VERSION ""

NS_ :

BS_:

BU_: BCM TPMS PEPS IC MP5 DDWS NV EATC TAC ESCL GW

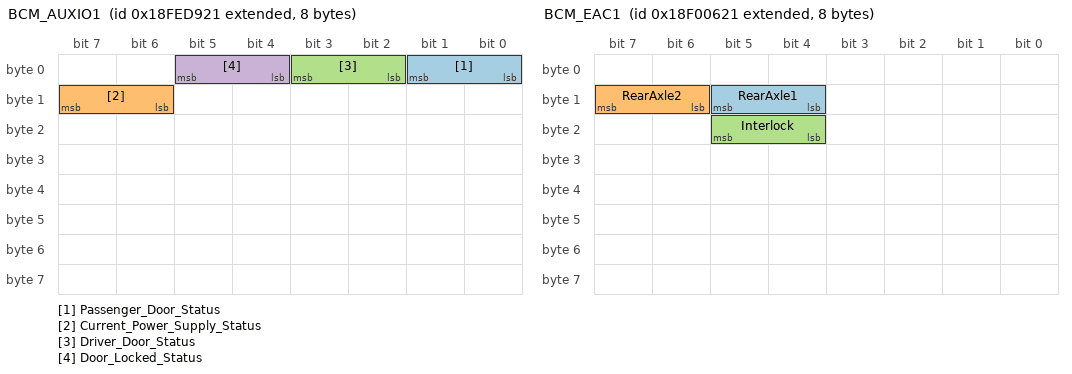
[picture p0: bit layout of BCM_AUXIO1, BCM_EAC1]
BO_ 2566838561 BCM_AUXIO1: 8 BCM
 SG_ Passenger_Door_Status : 0|2@1+ (1,0) [0|3] ""  PEPS,IC,MP5,GW
 SG_ Current_Power_Supply_Status : 14|2@1+ (1,0) [0|3] ""  MP5,EATC,GW
 SG_ Driver_Door_Status : 2|2@1+ (1,0) [0|3] ""  PEPS,IC,MP5,DDWS,GW
 SG_ Door_Locked_Status : 4|2@1+ (1,0) [0|3] ""  PEPS,GW

BO_ 2565867041 BCM_EAC1: 8 BCM
 SG_ RearAxle1 : 12|2@1+ (1,0) [0|3] ""  IC,MP5,GW
 SG_ RearAxle2 : 14|2@1+ (1,0) [0|3] ""  IC,MP5,GW
 SG_ Interlock : 20|2@1+ (1,0) [0|3] ""  IC,MP5,GW

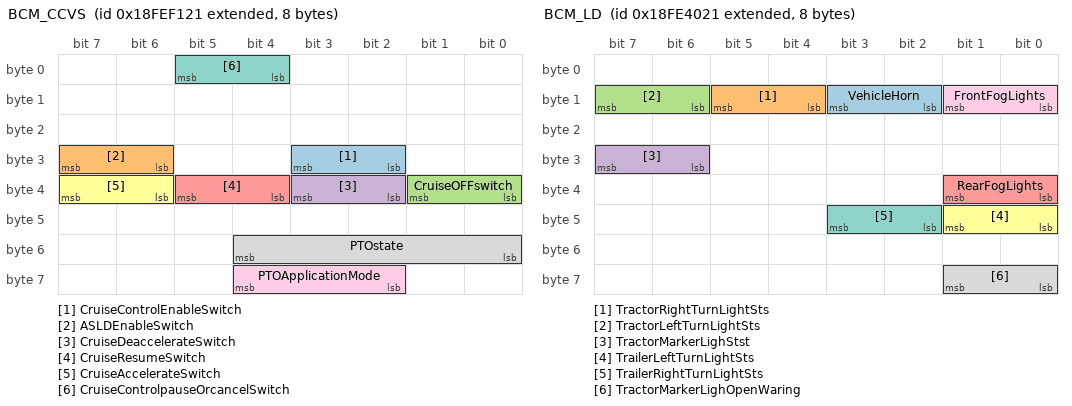
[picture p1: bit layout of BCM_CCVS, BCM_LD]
BO_ 2566844705 BCM_CCVS: 8 BCM
 SG_ CruiseControlEnableSwitch : 26|2@1+ (1,0) [0|3] ""  IC,GW
 SG_ ASLDEnableSwitch : 30|2@1+ (1,0) [0|3] ""  IC,GW
 SG_ CruiseOFFswitch : 32|2@1+ (1,0) [0|3] ""  IC,GW
 SG_ CruiseDeaccelerateSwitch : 34|2@1+ (1,0) [0|3] ""  IC,GW
 SG_ CruiseResumeSwitch : 36|2@1+ (1,0) [0|3] ""  IC,GW
 SG_ CruiseAccelerateSwitch : 38|2@1+ (1,0) [0|3] ""  IC,GW
 SG_ CruiseControlpauseOrcancelSwitch : 4|2@1+ (1,0) [0|3] ""  IC,GW
 SG_ PTOstate : 48|5@1+ (1,0) [0|31] ""  IC,GW
 SG_ PTOApplicationMode : 58|3@1+ (1,0) [0|7] ""  GW

BO_ 2566799393 BCM_LD: 8 BCM
 SG_ VehicleHorn : 10|2@1+ (1,0) [0|3] ""  TAC,GW
 SG_ TractorRightTurnLightSts : 12|2@1+ (1,0) [0|3] ""  IC,MP5,GW
 SG_ TractorLeftTurnLightSts : 14|2@1+ (1,0) [0|3] ""  IC,MP5,GW
 SG_ TractorMarkerLighStst : 30|2@1+ (1,0) [0|3] ""  IC,MP5,DDWS,NV,EATC,GW
 SG_ RearFogLights : 32|2@1+ (1,0) [0|3] ""  IC,MP5,GW
 SG_ TrailerLeftTurnLightSts : 40|2@1+ (1,0) [0|3] ""  IC,DDWS,GW
 SG_ TrailerRightTurnLightSts : 42|2@1+ (1,0) [0|3] ""  IC,DDWS,GW
 SG_ TractorMarkerLighOpenWaring : 56|2@1+ (1,0) [0|3] ""  IC,GW
 SG_ FrontFogLights : 8|2@1+ (1,0) [0|3] ""  IC,MP5,GW

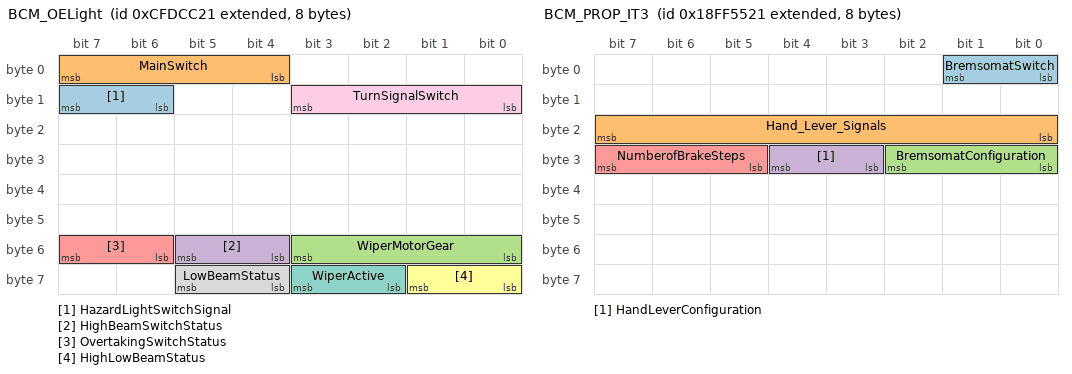
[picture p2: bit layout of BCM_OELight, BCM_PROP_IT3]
BO_ 2365443105 BCM_OELight: 8 BCM
 SG_ HazardLightSwitchSignal : 14|2@1+ (1,0) [0|3] ""  MP5,GW
 SG_ MainSwitch : 4|4@1+ (1,0) [0|15] ""  MP5,GW
 SG_ WiperMotorGear : 48|4@1+ (1,0) [0|15] ""  GW
 SG_ HighBeamSwitchStatus : 52|2@1+ (1,0) [0|3] ""  GW
 SG_ OvertakingSwitchStatus : 54|2@1+ (1,0) [0|3] ""  GW
 SG_ HighLowBeamStatus : 56|2@1+ (1,0) [0|3] ""  MP5,NV,GW
 SG_ WiperActive : 58|2@1+ (1,0) [0|3] ""  IC,GW
 SG_ LowBeamStatus : 60|2@1+ (1,0) [0|3] ""  MP5,NV,GW
 SG_ TurnSignalSwitch : 8|4@1+ (1,0) [0|15] ""  DDWS,GW

BO_ 2348875809 BCM_TC1: 8 BCM
 SG_ ReverseGear : 16|8@1+ (1,0) [0|255] ""  MP5,DDWS,GW
 SG_ RearviewMirrorHeating : 42|2@1+ (1,0) [0|3] ""  EATC,GW

BO_ 2566870305 BCM_PROP_IT3: 8 BCM
 SG_ BremsomatSwitch : 0|2@1+ (1,0) [0|3] ""  IC,GW
 SG_ Hand_Lever_Signals : 16|8@1+ (1,0) [0|63] ""  IC,GW
 SG_ BremsomatConfiguration : 24|3@1+ (1,0) [0|7] ""  IC,GW
 SG_ HandLeverConfiguration : 27|2@1+ (1,0) [0|3] ""  IC,GW
 SG_ NumberofBrakeSteps : 29|3@1+ (1,0) [0|7] ""  IC,GW

BO_ 2563768353 BCM_LightP: 8 BCM
 SG_ SwitBackLlluminatBrightPercent : 8|8@1+ (0.4,0) [0|100] "%"  PEPS,IC,EATC,GW

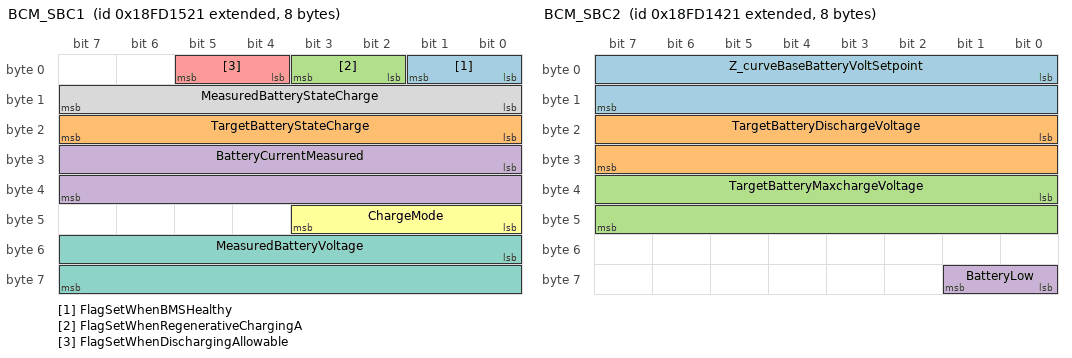
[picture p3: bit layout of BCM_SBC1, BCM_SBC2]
BO_ 2566722849 BCM_SBC1: 8 BCM
 SG_ FlagSetWhenBMSHealthy : 0|2@1+ (1,0) [0|3] ""  GW
 SG_ TargetBatteryStateCharge : 16|8@1+ (0.5,-10) [-10|110] ""  GW
 SG_ FlagSetWhenRegenerativeChargingA : 2|2@1+ (1,0) [0|3] ""  GW
 SG_ BatteryCurrentMeasured : 24|16@1+ (0.0305,-1600) [-1600|398.8] ""  GW
 SG_ FlagSetWhenDischargingAllowable : 4|2@1+ (1,0) [0|3] ""  GW
 SG_ ChargeMode : 40|4@1+ (1,0) [0|15] ""  GW
 SG_ MeasuredBatteryVoltage : 48|16@1+ (0.557,-1500) [-1500|35000] ""  GW
 SG_ MeasuredBatteryStateCharge : 8|8@1+ (0.5,-10) [-10|110] ""  GW

BO_ 2566722593 BCM_SBC2: 8 BCM
 SG_ Z_curveBaseBatteryVoltSetpoint : 0|16@1+ (0.557,-1500) [-1500|35000] "mV"  GW
 SG_ TargetBatteryDischargeVoltage : 16|16@1+ (0.557,-1500) [-1500|35000] "mV"  GW
 SG_ TargetBatteryMaxchargeVoltage : 32|16@1+ (0.557,-1500) [-1500|35000] "mV"  GW
 SG_ BatteryLow : 56|2@1+ (1,0) [0|3] ""  IC,GW

BO_ 2566860833 BCM_SOHStatus: 8 BCM
 SG_ SOH : 0|8@1+ (0.5,0) [0|100] "%"  IC
 SG_ SOHStatus : 8|2@1+ (1,0) [0|3] ""  IC

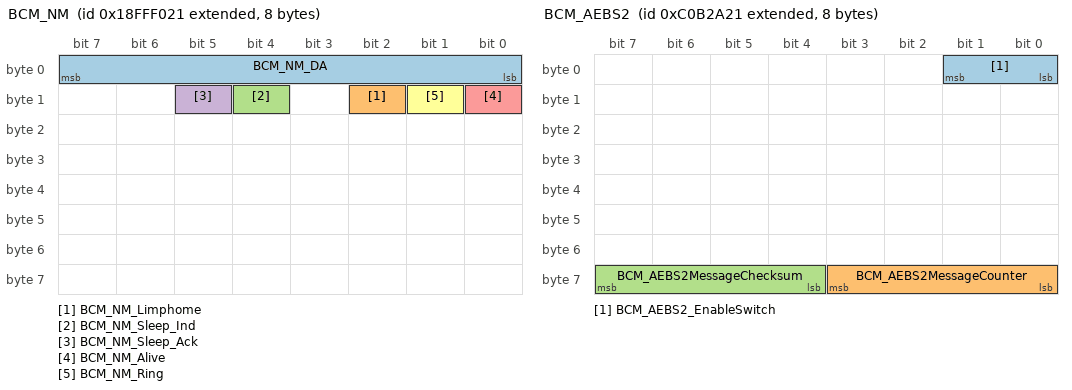
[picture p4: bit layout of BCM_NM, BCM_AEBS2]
BO_ 2566909985 BCM_NM: 8 BCM
 SG_ BCM_NM_DA : 0|8@1+ (1,0) [0|255] ""  PEPS,IC,MP5,EATC
 SG_ BCM_NM_Limphome : 10|1@1+ (1,0) [0|1] ""  PEPS,IC,MP5,EATC
 SG_ BCM_NM_Sleep_Ind : 12|1@1+ (1,0) [0|1] ""  PEPS,IC,MP5,EATC
 SG_ BCM_NM_Sleep_Ack : 13|1@1+ (1,0) [0|1] ""  PEPS,IC,MP5,EATC
 SG_ BCM_NM_Alive : 8|1@1+ (1,0) [0|1] ""  PEPS,IC,MP5,EATC
 SG_ BCM_NM_Ring : 9|1@1+ (1,0) [0|1] ""  PEPS,IC,MP5,EATC

BO_ 2564816929 BCM_CM1: 8 BCM
 SG_ ParticulatetrapregenerationInhib : 40|2@1+ (1,0) [0|3] ""  GW
 SG_ ParticulatetrapregenerationForce : 42|2@1+ (1,0) [0|3] ""  GW

BO_ 2566803745 BCM_ACC2: 8 BCM
 SG_ BCM_ACCusagedemand : 0|2@1+ (1,0) [0|3] ""  GW
 SG_ BCM_RequestedACCDistanceMode : 5|3@1+ (1,0) [0|7] ""  GW

BO_ 2349541921 BCM_AEBS2: 8 BCM
 SG_ BCM_AEBS2_EnableSwitch : 0|2@1+ (1,0) [0|3] ""  IC,GW
 SG_ BCM_AEBS2MessageCounter : 56|4@1+ (1,0) [0|15] ""  IC,GW
 SG_ BCM_AEBS2MessageChecksum : 60|4@1+ (1,0) [0|15] ""  IC,GW

BO_ 2566834721 BCMDM1CLuster: 8 BCM

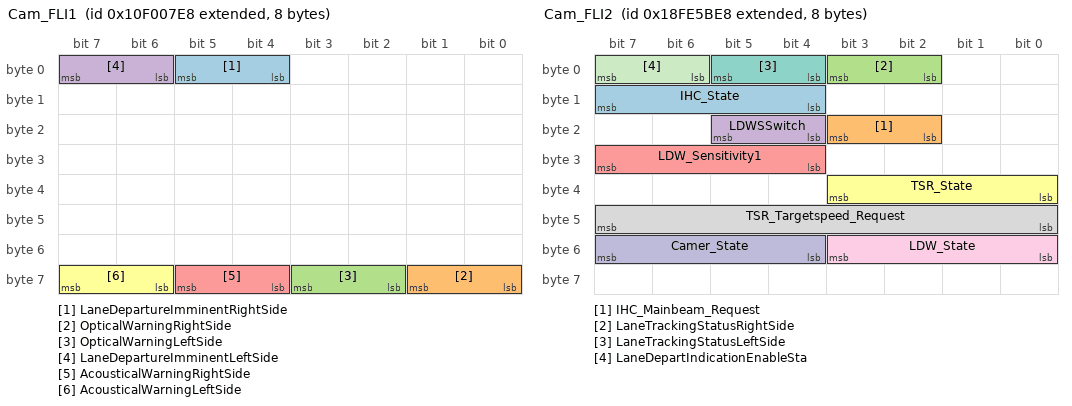
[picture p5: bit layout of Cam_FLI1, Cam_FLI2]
BO_ 2431649768 Cam_FLI1: 8 GW
 SG_ LaneDepartureImminentRightSide : 4|2@1+ (1,0) [0|3] ""  IC
 SG_ OpticalWarningRightSide : 56|2@1+ (1,0) [0|3] ""  IC
 SG_ OpticalWarningLeftSide : 58|2@1+ (1,0) [0|3] ""  IC
 SG_ LaneDepartureImminentLeftSide : 6|2@1+ (1,0) [0|3] ""  IC
 SG_ AcousticalWarningRightSide : 60|2@1+ (1,0) [0|3] ""  IC
 SG_ AcousticalWarningLeftSide : 62|2@1+ (1,0) [0|3] ""  IC

BO_ 2566806504 Cam_FLI2: 8 GW
 SG_ IHC_State : 12|4@1+ (1,0) [0|15] ""  IC,MP5
 SG_ IHC_Mainbeam_Request : 18|2@1+ (1,0) [0|3] ""  BCM
 SG_ LaneTrackingStatusRightSide : 2|2@1+ (1,0) [0|3] ""  IC
 SG_ LDWSSwitch : 20|2@1+ (1,0) [0|3] ""  IC,MP5
 SG_ LDW_Sensitivity1 : 28|4@1+ (1,0) [0|15] ""  IC,MP5
 SG_ TSR_State : 32|4@1+ (1,0) [0|15] ""  IC,MP5
 SG_ LaneTrackingStatusLeftSide : 4|2@1+ (1,0) [0|3] ""  IC
 SG_ TSR_Targetspeed_Request : 40|8@1+ (1,0) [0|255] ""  IC
 SG_ LDW_State : 48|4@1+ (1,0) [0|15] ""  IC
 SG_ Camer_State : 52|4@1+ (1,0) [0|15] ""  IC,MP5
 SG_ LaneDepartIndicationEnableSta : 6|2@1+ (1,0) [0|3] ""  IC

BO_ 2566834920 CAM_DM1CLuster: 8 GW

BO_ 2632777704 CAM_BAME: 8 GW

BO_ 2632712168 CAM_PACKET: 8 GW

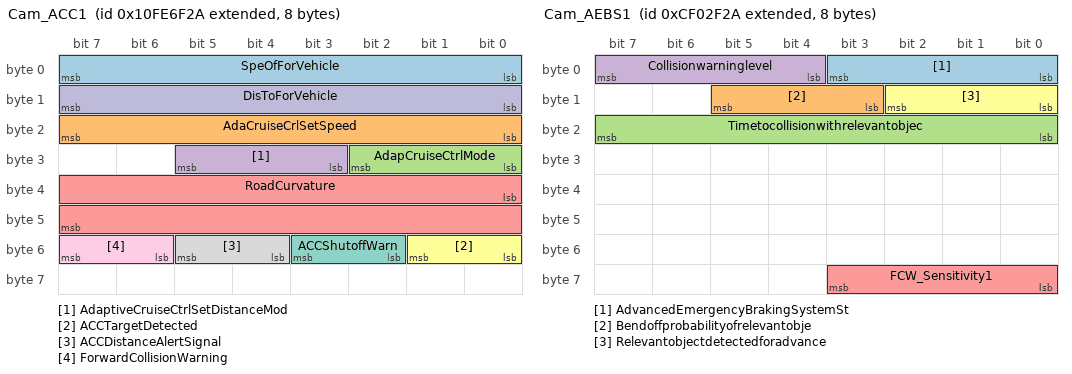
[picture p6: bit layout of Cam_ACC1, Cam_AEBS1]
BO_ 2432593706 Cam_ACC1: 8 GW
 SG_ SpeOfForVehicle : 0|8@1+ (1,0) [0|250] "km/h"  IC,MP5
 SG_ AdaCruiseCrlSetSpeed : 16|8@1+ (1,0) [0|250] "km/h"  IC,MP5
 SG_ AdapCruiseCtrlMode : 24|3@1+ (1,0) [0|7] ""  IC,MP5
 SG_ AdaptiveCruiseCtrlSetDistanceMod : 27|3@1+ (1,0) [0|7] ""  IC,MP5
 SG_ RoadCurvature : 32|16@1+ (0.0078125,-250) [-250|251.992] "1/km"  IC,MP5
 SG_ ACCTargetDetected : 48|2@1+ (1,0) [0|3] ""  IC,MP5
 SG_ ACCShutoffWarn : 50|2@1+ (1,0) [0|3] ""  IC,MP5
 SG_ ACCDistanceAlertSignal : 52|2@1+ (1,0) [0|3] ""  IC,MP5
 SG_ ForwardCollisionWarning : 54|2@1+ (1,0) [0|3] ""  IC,MP5
 SG_ DisToForVehicle : 8|8@1+ (1,0) [0|250] "m"  IC,MP5

BO_ 2364550954 Cam_AEBS1: 8 GW
 SG_ AdvancedEmergencyBrakingSystemSt : 0|4@1+ (1,0) [0|15] ""  IC,MP5
 SG_ Bendoffprobabilityofrelevantobje : 11|3@1+ (1,0) [0|7] "" Vector__XXX
 SG_ Timetocollisionwithrelevantobjec : 16|8@1+ (0.05,0) [0|12.5] "s/bit" Vector__XXX
 SG_ Collisionwarninglevel : 4|4@1+ (1,0) [0|15] ""  IC
 SG_ FCW_Sensitivity1 : 56|4@1+ (1,0) [0|15] ""  IC
 SG_ Relevantobjectdetectedforadvance : 8|3@1+ (1,0) [0|7] ""  IC

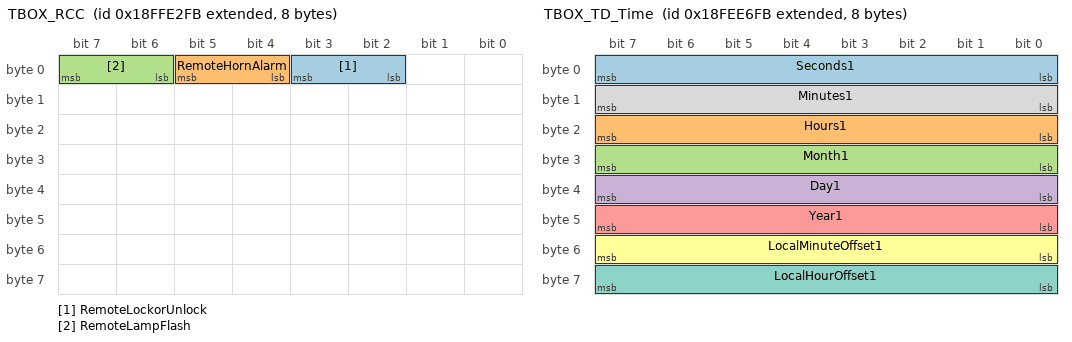
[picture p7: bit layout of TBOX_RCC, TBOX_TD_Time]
BO_ 2566906619 TBOX_RCC: 8 GW
 SG_ RemoteLockorUnlock : 2|2@1+ (1,0) [0|3] ""  BCM
 SG_ RemoteHornAlarm : 4|2@1+ (1,0) [0|3] ""  BCM
 SG_ RemoteLampFlash : 6|2@1+ (1,0) [0|3] ""  BCM

BO_ 2566906875 TBOX_RC_TRC: 8 GW
 SG_ VINStateResponse : 2|2@1+ (1,0) [0|3] ""  IC
 SG_ LoanState : 4|4@1+ (1,0) [0|15] ""  IC

BO_ 2566842107 TBOX_TD_Time: 8 GW
 SG_ Seconds1 : 0|8@1+ (0.25,0) [0|59.75] "s"  IC
 SG_ Hours1 : 16|8@1+ (1,0) [0|23] "hr"  IC
 SG_ Month1 : 24|8@1+ (1,0) [0|12] "month"  IC
 SG_ Day1 : 32|8@1+ (0.25,0) [1|31] "days"  IC
 SG_ Year1 : 40|8@1+ (1,1985) [1985|2235] "year"  IC
 SG_ LocalMinuteOffset1 : 48|8@1+ (1,-125) [-59|59] "min"  IC
 SG_ LocalHourOffset1 : 56|8@1+ (1,-125) [-23|23] "hour"  IC
 SG_ Minutes1 : 8|8@1+ (1,0) [0|59] "min"  IC

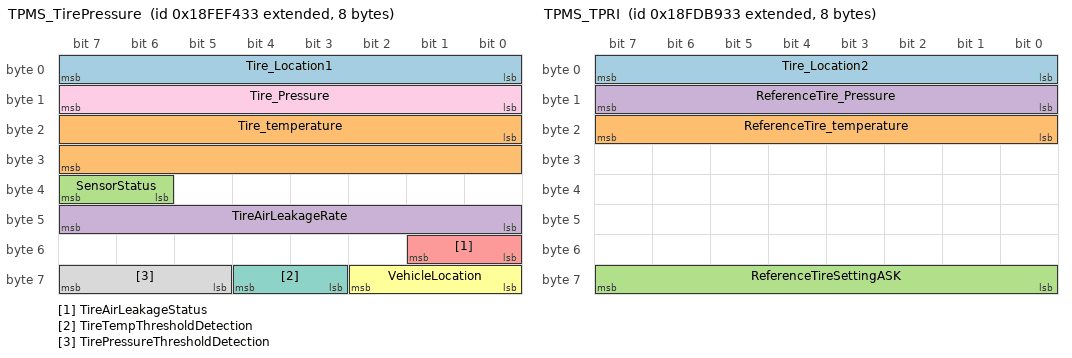
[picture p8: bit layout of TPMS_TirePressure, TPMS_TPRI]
BO_ 2566845491 TPMS_TirePressure: 8 TPMS
 SG_ Tire_Location1 : 0|8@1+ (1,0) [0|255] ""  IC,MP5,GW
 SG_ Tire_temperature : 16|16@1+ (0.03125,-273) [-273|1734.96875] ""  IC,MP5,GW
 SG_ SensorStatus : 38|2@1+ (1,0) [0|3] ""  IC,MP5,GW
 SG_ TireAirLeakageRate : 40|8@1+ (0.1,0) [0|25.5] "Pa/s"  MP5,GW
 SG_ TireAirLeakageStatus : 48|2@1+ (1,0) [0|3] ""  MP5,GW
 SG_ VehicleLocation : 56|3@1+ (1,0) [0|7] ""  GW
 SG_ TireTempThresholdDetection : 59|2@1+ (1,0) [0|3] ""  MP5,GW
 SG_ TirePressureThresholdDetection : 61|3@1+ (1,0) [0|7] ""  MP5,GW
 SG_ Tire_Pressure : 8|8@1+ (5.5,0) [0|1397] "kPa"  IC,MP5,GW

BO_ 2566764851 TPMS_TPRI: 8 TPMS
 SG_ Tire_Location2 : 0|8@1+ (1,0) [0|255] ""  GW
 SG_ ReferenceTire_temperature : 16|8@1+ (1,0) [0|125] ""  GW
 SG_ ReferenceTireSettingASK : 56|8@1+ (1,0) [0|255] ""  GW
 SG_ ReferenceTire_Pressure : 8|8@1+ (5.5,0) [0|1391] "kPa"  GW

BO_ 2566834739 TPMSDM1CLuster: 8 TPMS

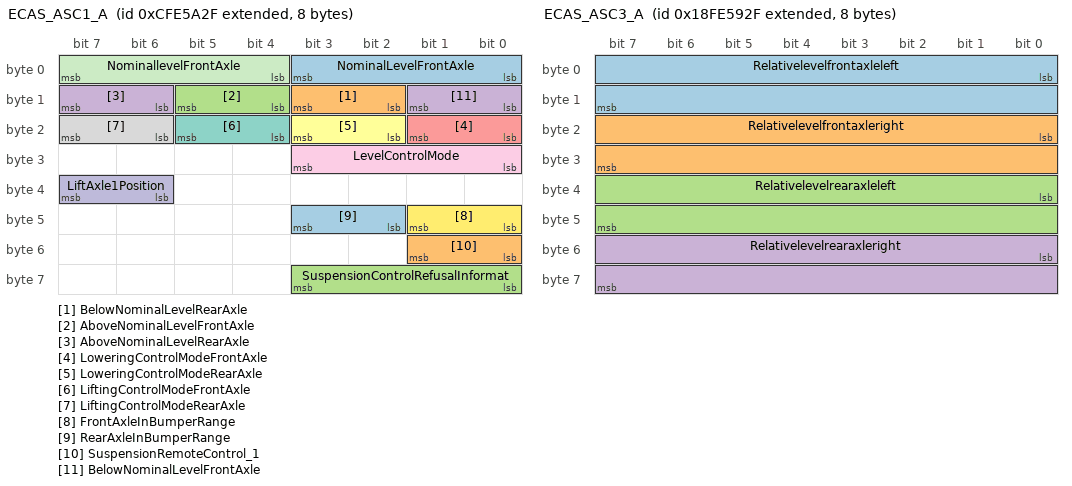
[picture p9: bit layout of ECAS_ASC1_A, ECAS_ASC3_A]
BO_ 2365479471 ECAS_ASC1_A: 8 GW
 SG_ NominalLevelFrontAxle : 0|4@1+ (1,0) [0|15] "" Vector__XXX
 SG_ BelowNominalLevelRearAxle : 10|2@1+ (1,0) [0|3] "" Vector__XXX
 SG_ AboveNominalLevelFrontAxle : 12|2@1+ (1,0) [0|3] "" Vector__XXX
 SG_ AboveNominalLevelRearAxle : 14|2@1+ (1,0) [0|3] "" Vector__XXX
 SG_ LoweringControlModeFrontAxle : 16|2@1+ (1,0) [0|3] "" Vector__XXX
 SG_ LoweringControlModeRearAxle : 18|2@1+ (1,0) [0|3] "" Vector__XXX
 SG_ LiftingControlModeFrontAxle : 20|2@1+ (1,0) [0|3] "" Vector__XXX
 SG_ LiftingControlModeRearAxle : 22|2@1+ (1,0) [0|3] "" Vector__XXX
 SG_ LevelControlMode : 24|4@1+ (1,0) [0|15] "" Vector__XXX
 SG_ LiftAxle1Position : 38|2@1+ (1,0) [0|3] "" Vector__XXX
 SG_ NominallevelFrontAxle : 4|4@1+ (1,0) [0|15] ""  IC
 SG_ FrontAxleInBumperRange : 40|2@1+ (1,0) [0|3] "" Vector__XXX
 SG_ RearAxleInBumperRange : 42|2@1+ (1,0) [0|3] "" Vector__XXX
 SG_ SuspensionRemoteControl_1 : 48|2@1+ (1,0) [0|3] "" Vector__XXX
 SG_ SuspensionControlRefusalInformat : 56|4@1+ (1,0) [0|15] "" Vector__XXX
 SG_ BelowNominalLevelFrontAxle : 8|2@1+ (1,0) [0|3] "" Vector__XXX

BO_ 2566805807 ECAS_ASC3_A: 8 GW
 SG_ Relativelevelfrontaxleleft : 0|16@1+ (0.1,-3200) [-3200|3225.5] "mm/bit" Vector__XXX
 SG_ Relativelevelfrontaxleright : 16|16@1+ (0.1,-3200) [-3200|3225.5] "mm/bit"  IC
 SG_ Relativelevelrearaxleleft : 32|16@1+ (0.1,-3200) [-3200|3225.5] "mm/bit"  IC
 SG_ Relativelevelrearaxleright : 48|16@1+ (0.1,-3200) [-3200|3225.5] "mm/bit"  IC

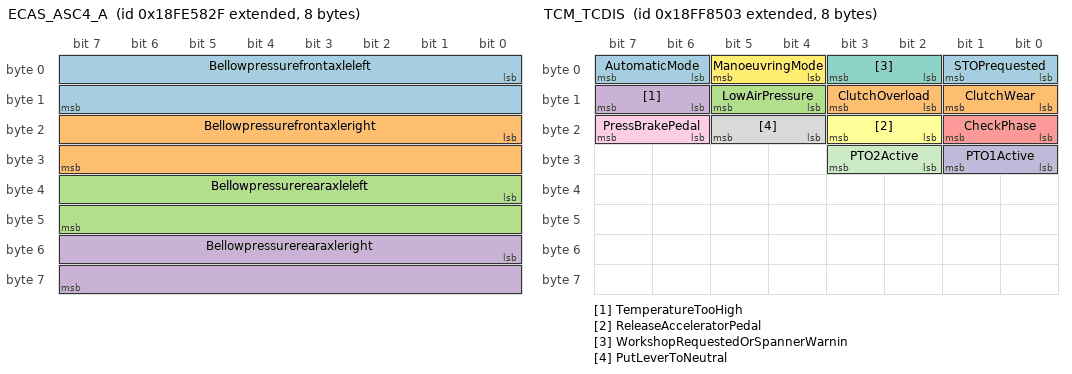
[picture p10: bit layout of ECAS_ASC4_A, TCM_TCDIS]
BO_ 2566805551 ECAS_ASC4_A: 8 GW
 SG_ Bellowpressurefrontaxleleft : 0|16@1+ (0.1,0) [0|6425.5] "kPa" Vector__XXX
 SG_ Bellowpressurefrontaxleright : 16|16@1+ (0.1,0) [0|6425.5] "kPa"  IC
 SG_ Bellowpressurerearaxleleft : 32|16@1+ (0.1,0) [0|6425.5] "kPa"  IC
 SG_ Bellowpressurerearaxleright : 48|16@1+ (0.1,0) [0|6425.5] "kPa"  IC

BO_ 2566882563 TCM_TCDIS: 8 GW
 SG_ STOPrequested : 0|2@1+ (1,0) [0|3] ""  IC
 SG_ ClutchOverload : 10|2@1+ (1,0) [0|3] ""  IC
 SG_ LowAirPressure : 12|2@1+ (1,0) [0|3] ""  IC
 SG_ TemperatureTooHigh : 14|2@1+ (1,0) [0|3] ""  IC
 SG_ CheckPhase : 16|2@1+ (1,0) [0|3] ""  IC
 SG_ ReleaseAcceleratorPedal : 18|2@1+ (1,0) [0|3] ""  IC
 SG_ WorkshopRequestedOrSpannerWarnin : 2|2@1+ (1,0) [0|3] ""  IC
 SG_ PutLeverToNeutral : 20|2@1+ (1,0) [0|3] ""  IC
 SG_ PressBrakePedal : 22|2@1+ (1,0) [0|3] ""  IC
 SG_ PTO1Active : 24|2@1+ (1,0) [0|3] ""  IC
 SG_ PTO2Active : 26|2@1+ (1,0) [0|3] ""  IC
 SG_ ManoeuvringMode : 4|2@1+ (1,0) [0|3] ""  IC
 SG_ AutomaticMode : 6|2@1+ (1,0) [0|3] ""  IC
 SG_ ClutchWear : 8|2@1+ (1,0) [0|3] ""  IC

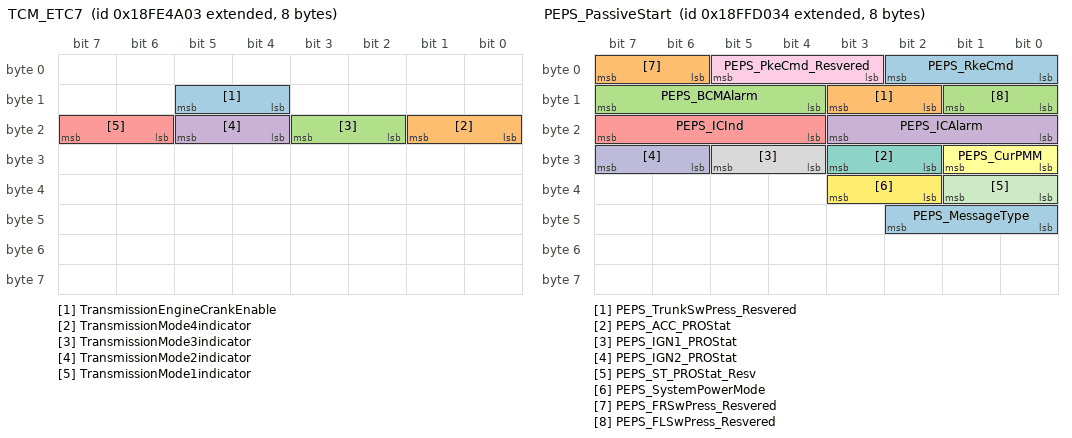
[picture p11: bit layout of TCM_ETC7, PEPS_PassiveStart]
BO_ 2566801923 TCM_ETC7: 8 GW
 SG_ TransmissionEngineCrankEnable : 12|2@1+ (1,0) [0|3] "" Vector__XXX
 SG_ TransmissionMode4indicator : 16|2@1+ (1,0) [0|3] "" Vector__XXX
 SG_ TransmissionMode3indicator : 18|2@1+ (1,0) [0|3] "" Vector__XXX
 SG_ TransmissionMode2indicator : 20|2@1+ (1,0) [0|3] ""  IC
 SG_ TransmissionMode1indicator : 22|2@1+ (1,0) [0|3] "" Vector__XXX

BO_ 2566834691 TCM_DM1CLuster: 8 GW

BO_ 2632777475 TCM_BAME: 8 GW

BO_ 2632711939 TCM_PACKET: 8 GW

BO_ 2566834735 ECAS_DM1CLuster: 8 GW
 SG_ AmberWarningLampStatus : 2|2@1+ (1,0) [0|3] ""  IC

BO_ 2632777519 ECAS_BAME: 8 GW

BO_ 2632711983 ECAS_PACKET: 8 GW

BO_ 2566901812 PEPS_PassiveStart: 8 PEPS
 SG_ PEPS_RkeCmd : 0|3@1+ (1,0) [0|7] ""  BCM,GW
 SG_ PEPS_TrunkSwPress_Resvered : 10|2@1+ (1,0) [0|3] ""  BCM,GW
 SG_ PEPS_BCMAlarm : 12|4@1+ (1,0) [0|15] ""  BCM,GW
 SG_ PEPS_ICAlarm : 16|4@1+ (1,0) [0|15] ""  IC,GW
 SG_ PEPS_ICInd : 20|4@1+ (1,0) [0|15] ""  IC,GW
 SG_ PEPS_CurPMM : 24|2@1+ (1,0) [0|3] ""  BCM,IC,GW
 SG_ PEPS_ACC_PROStat : 26|2@1+ (1,0) [0|3] ""  BCM,IC,GW
 SG_ PEPS_IGN1_PROStat : 28|2@1+ (1,0) [0|3] ""  BCM,IC,GW
 SG_ PEPS_PkeCmd_Resvered : 3|3@1+ (1,0) [0|7] ""  BCM,GW
 SG_ PEPS_IGN2_PROStat : 30|2@1+ (1,0) [0|3] ""  BCM,IC,GW
 SG_ PEPS_ST_PROStat_Resv : 32|2@1+ (1,0) [0|3] ""  BCM,IC,GW
 SG_ PEPS_SystemPowerMode : 34|2@1+ (1,0) [0|3] ""  BCM,IC,ESCL,GW
 SG_ PEPS_MessageType : 40|3@1+ (1,0) [0|7] ""  GW
 SG_ PEPS_FRSwPress_Resvered : 6|2@1+ (1,0) [0|3] ""  BCM,GW
 SG_ PEPS_FLSwPress_Resvered : 8|2@1+ (1,0) [0|3] ""  BCM,GW

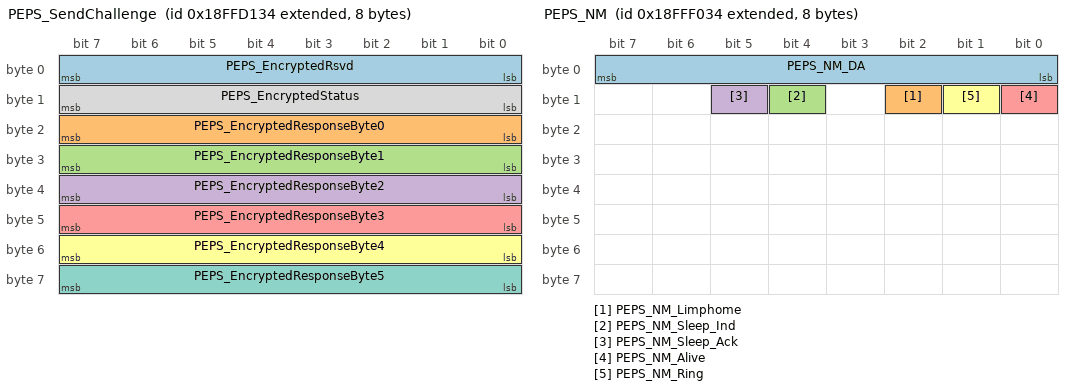
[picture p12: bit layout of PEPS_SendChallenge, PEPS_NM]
BO_ 2566902068 PEPS_SendChallenge: 8 PEPS
 SG_ PEPS_EncryptedRsvd : 0|8@1+ (1,0) [0|255] ""  GW
 SG_ PEPS_EncryptedResponseByte0 : 16|8@1+ (1,0) [0|255] ""  GW
 SG_ PEPS_EncryptedResponseByte1 : 24|8@1+ (1,0) [0|255] ""  GW
 SG_ PEPS_EncryptedResponseByte2 : 32|8@1+ (1,0) [0|255] ""  GW
 SG_ PEPS_EncryptedResponseByte3 : 40|8@1+ (1,0) [0|255] ""  GW
 SG_ PEPS_EncryptedResponseByte4 : 48|8@1+ (1,0) [0|255] ""  GW
 SG_ PEPS_EncryptedResponseByte5 : 56|8@1+ (1,0) [0|255] ""  GW
 SG_ PEPS_EncryptedStatus : 8|8@1+ (1,0) [0|255] ""  GW

BO_ 2566834740 IMMO_DM1Cluster: 8 GW

BO_ 2632777524 IMMO_BAME: 8 GW

BO_ 2632711988 IMMO_PACKET: 8 GW

BO_ 2566834943 PEPS_DM1Cluster: 8 PEPS

BO_ 2566910004 PEPS_NM: 8 PEPS
 SG_ PEPS_NM_DA : 0|8@1+ (1,0) [0|255] ""  BCM,IC,MP5,EATC
 SG_ PEPS_NM_Limphome : 10|1@1+ (1,0) [0|1] ""  BCM,IC,MP5,EATC
 SG_ PEPS_NM_Sleep_Ind : 12|1@1+ (1,0) [0|1] ""  BCM,IC,MP5,EATC
 SG_ PEPS_NM_Sleep_Ack : 13|1@1+ (1,0) [0|1] ""  BCM,IC,MP5,EATC
 SG_ PEPS_NM_Alive : 8|1@1+ (1,0) [0|1] ""  BCM,IC,MP5,EATC
 SG_ PEPS_NM_Ring : 9|1@1+ (1,0) [0|1] ""  BCM,IC,MP5,EATC

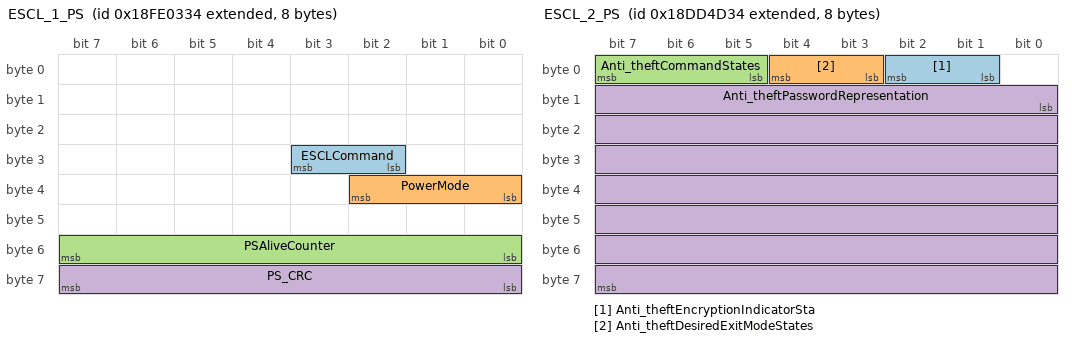
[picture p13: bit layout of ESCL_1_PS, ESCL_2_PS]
BO_ 2566783796 ESCL_1_PS: 8 PEPS
 SG_ ESCLCommand : 26|2@1+ (1,0) [0|3] ""  ESCL
 SG_ PowerMode : 32|3@1+ (1,0) [0|7] ""  ESCL
 SG_ PSAliveCounter : 48|8@1+ (1,0) [0|255] ""  ESCL
 SG_ PS_CRC : 56|8@1+ (1,0) [0|255] ""  ESCL

BO_ 2564640052 ESCL_2_PS: 8 PEPS
 SG_ Anti_theftEncryptionIndicatorSta : 1|2@1+ (1,0) [0|3] ""  ESCL
 SG_ Anti_theftDesiredExitModeStates : 3|2@1+ (1,0) [0|3] ""  ESCL
 SG_ Anti_theftCommandStates : 5|3@1+ (1,0) [0|7] ""  ESCL
 SG_ Anti_theftPasswordRepresentation : 8|56@1+ (1,0) [0|7.20575940379279E+016] ""  ESCL

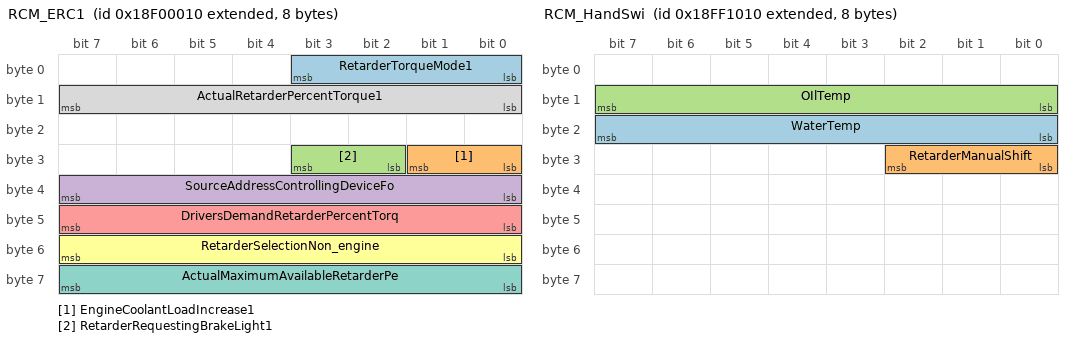
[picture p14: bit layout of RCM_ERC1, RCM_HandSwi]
BO_ 2565865488 RCM_ERC1: 8 GW
 SG_ RetarderTorqueMode1 : 0|4@1+ (1,0) [0|15] ""  IC
 SG_ EngineCoolantLoadIncrease1 : 24|2@1+ (1,0) [0|1] ""  IC
 SG_ RetarderRequestingBrakeLight1 : 26|2@1+ (1,0) [0|3] ""  BCM
 SG_ SourceAddressControllingDeviceFo : 32|8@1+ (1,0) [0|253] "" Vector__XXX
 SG_ DriversDemandRetarderPercentTorq : 40|8@1+ (1,-125) [-125|125] "%" Vector__XXX
 SG_ RetarderSelectionNon_engine : 48|8@1+ (0.4,0) [0|100] "%" Vector__XXX
 SG_ ActualMaximumAvailableRetarderPe : 56|8@1+ (1,-125) [-125|125] "%" Vector__XXX
 SG_ ActualRetarderPercentTorque1 : 8|8@1- (1,-125) [-125|125] "%"  BCM,IC

BO_ 2566852624 RCM_HandSwi: 8 GW
 SG_ WaterTemp : 16|8@1- (1,-40) [-40|215] "℃" Vector__XXX
 SG_ RetarderManualShift : 24|3@1+ (1,0) [0|7] ""  BCM
 SG_ OIlTemp : 8|8@1- (1,-40) [-40|215] "℃" Vector__XXX

BO_ 2566834704 RCM_DM1CLuster: 8 GW

BO_ 2632777488 RCM_BAME: 8 GW

BO_ 2632711952 RCM_PACKET: 8 GW

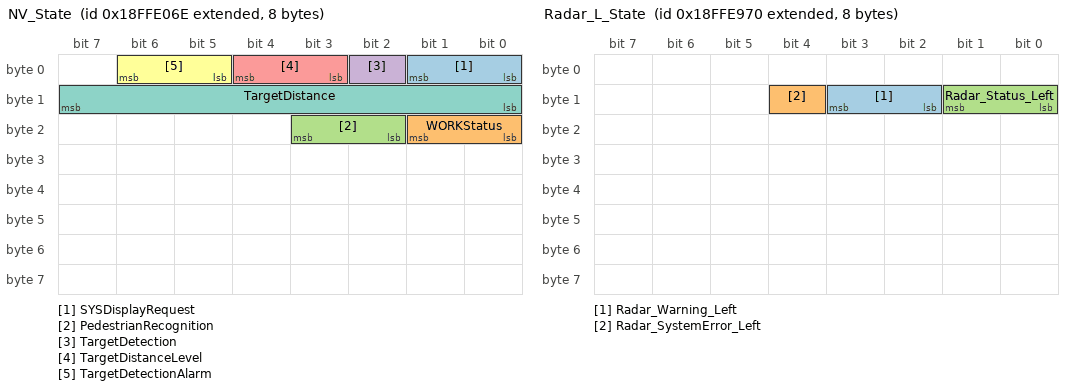
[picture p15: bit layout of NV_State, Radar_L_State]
BO_ 2566905966 NV_State: 8 NV
 SG_ SYSDisplayRequest : 0|2@1+ (1,0) [0|1] ""  IC
 SG_ WORKStatus : 16|2@1+ (1,0) [0|3] ""  IC
 SG_ PedestrianRecognition : 18|2@1+ (1,0) [0|3] ""  IC
 SG_ TargetDetection : 2|1@1+ (1,0) [0|1] ""  IC
 SG_ TargetDistanceLevel : 3|2@1+ (1,0) [0|3] ""  IC
 SG_ TargetDetectionAlarm : 5|2@1+ (1,0) [0|1] ""  IC
 SG_ TargetDistance : 8|8@1+ (1,0) [0|250] "m"  IC

BO_ 2566834798 NV_DM1Cluster: 8 NV

BO_ 2566908272 Radar_L_State: 8 GW
 SG_ Radar_Warning_Left : 10|2@1+ (1,0) [0|3] ""  IC
 SG_ Radar_SystemError_Left : 12|1@1+ (1,0) [0|1] ""  IC
 SG_ Radar_Status_Left : 8|2@1+ (1,0) [0|3] "" Vector__XXX

BO_ 2566834800 BSDL_DM1Cluster: 8 GW

BO_ 2632777584 RadarL_BAME: 8 GW

BO_ 2632712048 RadarL_PACKET: 8 GW

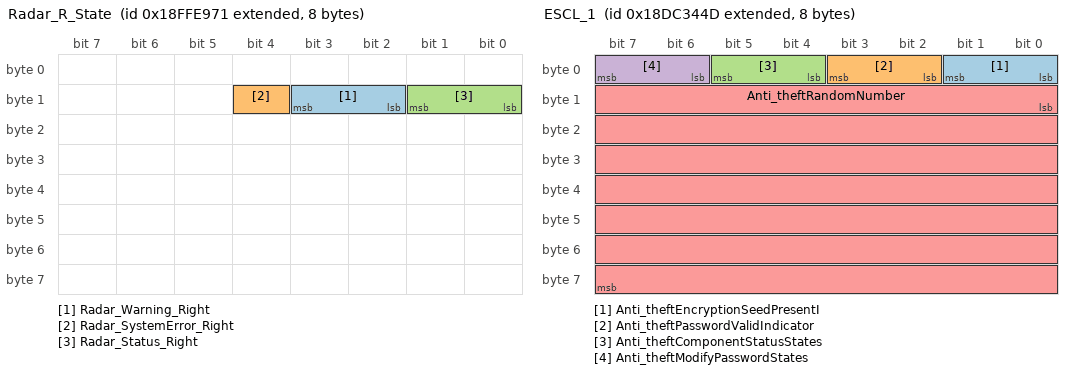
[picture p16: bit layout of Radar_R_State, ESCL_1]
BO_ 2566908273 Radar_R_State: 8 GW
 SG_ Radar_Warning_Right : 10|2@1+ (1,0) [0|3] ""  IC
 SG_ Radar_SystemError_Right : 12|1@1+ (1,0) [0|1] ""  IC
 SG_ Radar_Status_Right : 8|2@1+ (1,0) [0|3] "" Vector__XXX

BO_ 2566834801 BSDR_DM1Cluster: 8 GW

BO_ 2632777585 RadarR_BAME: 8 GW

BO_ 2632712049 RadarR_PACKET: 8 GW

BO_ 2564568141 ESCL_1: 8 ESCL
 SG_ Anti_theftEncryptionSeedPresentI : 0|2@1+ (1,0) [0|3] ""  PEPS
 SG_ Anti_theftPasswordValidIndicator : 2|2@1+ (1,0) [0|3] ""  PEPS
 SG_ Anti_theftComponentStatusStates : 4|2@1+ (1,0) [0|3] ""  PEPS
 SG_ Anti_theftModifyPasswordStates : 6|2@1+ (1,0) [0|3] ""  PEPS
 SG_ Anti_theftRandomNumber : 8|56@1+ (1,0) [0|7.20575940379279E+016] ""  PEPS

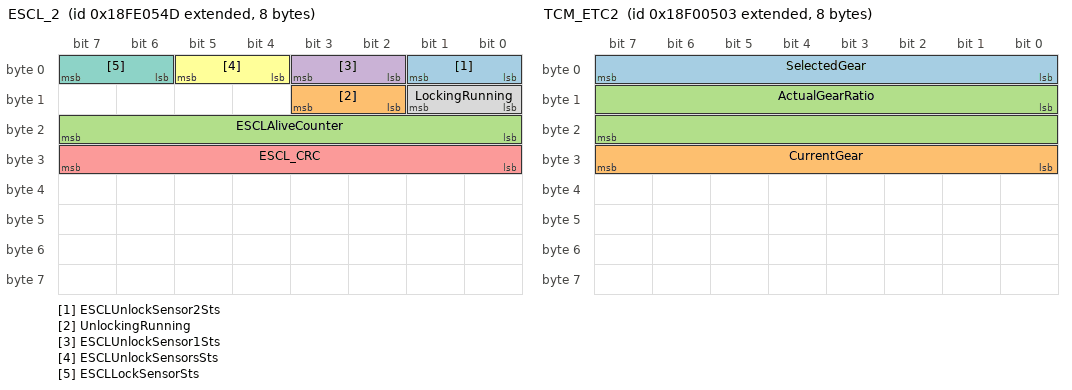
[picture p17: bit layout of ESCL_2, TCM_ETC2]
BO_ 2566784333 ESCL_2: 8 ESCL
 SG_ ESCLUnlockSensor2Sts : 0|2@1+ (1,0) [0|3] ""  PEPS
 SG_ UnlockingRunning : 10|2@1+ (1,0) [0|3] ""  PEPS
 SG_ ESCLAliveCounter : 16|8@1+ (1,0) [0|255] ""  PEPS
 SG_ ESCLUnlockSensor1Sts : 2|2@1+ (1,0) [0|3] ""  PEPS
 SG_ ESCL_CRC : 24|8@1+ (1,0) [0|255] ""  PEPS
 SG_ ESCLUnlockSensorsSts : 4|2@1+ (1,0) [0|3] ""  PEPS
 SG_ ESCLLockSensorSts : 6|2@1+ (1,0) [0|3] ""  PEPS
 SG_ LockingRunning : 8|2@1+ (1,0) [0|3] ""  PEPS

BO_ 2566834765 ESCL_DM1Cluster: 8 ESCL

BO_ 2565866755 TCM_ETC2: 8 GW
 SG_ SelectedGear : 0|8@1+ (1,-125) [-125|125] "" Vector__XXX
 SG_ CurrentGear : 24|8@1+ (1,-125) [-125|125] ""  PEPS
 SG_ ActualGearRatio : 8|16@1+ (0.001,0) [0|64.255] "" Vector__XXX

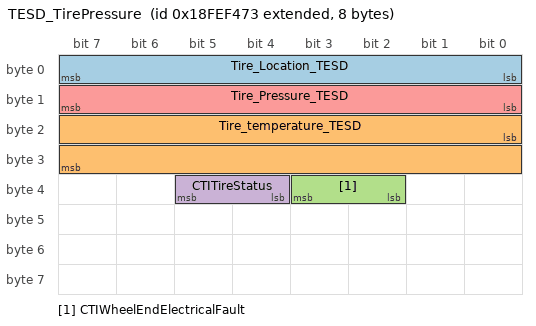
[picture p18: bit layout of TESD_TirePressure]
BO_ 2566845555 TESD_TirePressure: 8 GW
 SG_ Tire_Location_TESD : 0|8@1+ (1,0) [0|255] ""  IC
 SG_ Tire_temperature_TESD : 16|16@1+ (0.03125,-273) [-273|1734.96875] ""  IC
 SG_ CTIWheelEndElectricalFault : 34|2@1+ (1,0) [0|3] ""  IC
 SG_ CTITireStatus : 36|2@1+ (1,0) [0|3] ""  IC
 SG_ Tire_Pressure_TESD : 8|8@1+ (5.5,0) [0|1391.5] "kPa"  IC

BO_ 2566834803 TESDDM1CLuster: 8 GW

BO_ 2632777587 TESD_BAME: 8 GW

BO_ 2632712051 TESD_PACKET: 8 GW

BO_ 2566834725 GW_DM1CLuster: 8 GW

BO_ 2564432369 Diag_PhyReq_BCM: 8 GW

BO_ 2564436977 Diag_PhyReq_TPMS: 8 GW

BO_ 2564489201 Diag_PhyReq_PEPS: 8 GW

BO_ 2564429809 Diag_PhyReq_IC: 8 GW

BO_ 2564443377 Diag_PhyReq_MP5: 8 GW

BO_ 2564483057 Diag_PhyReq_DDWS: 8 GW

BO_ 2564452081 Diag_PhyReq_NV: 8 GW

BO_ 2564430321 Diag_PhyReq_EATC: 8 GW

BO_ 2564484849 Diag_PhyReq_TAC: 8 GW

BO_ 2564443633 Diag_PhyReq_ESCL: 8 GW

BO_ 2564485409 Diag_Resp_BCM: 8 BCM

BO_ 2564485427 Diag_Resp_TPMS: 8 TPMS

BO_ 2564485428 Diag_Resp_PEPS: 8 PEPS

BO_ 2564485399 Diag_Resp_IC: 8 IC

BO_ 2564485452 Diag_Resp_MP5: 8 MP5

BO_ 2564485607 Diag_Resp_DDWS: 8 DDWS

BO_ 2564485486 Diag_Resp_NV: 8 NV

BO_ 2564485401 Diag_Resp_EATC: 8 EATC

BO_ 2564485614 Diag_Resp_TAC: 8 TAC

BO_ 2564485453 Diag_Resp_ESCL: 8 ESCL

BO_ 2564554737 Diag_FuncReq: 8 GW

BO_ 2564502513 Diag_FuncReq_ESCL: 8 GW

BO_ 2566909989 GW_BODCAN_NM: 8 GW

CM_ SG_ 2566838561 Passenger_Door_Status "副司机侧车门状态";
CM_ SG_ 2566838561 Current_Power_Supply_Status "钥匙状态";
CM_ SG_ 2566838561 Driver_Door_Status "司机侧车门状态";
CM_ SG_ 2566838561 Door_Locked_Status "司机侧锁状态";
CM_ SG_ 2565867041 RearAxle1 "Rear Axle 1 (Differential Lock 1)";
CM_ SG_ 2565867041 RearAxle2 "Rear Axle 2 (Differential Lock 2)";
CM_ SG_ 2565867041 Interlock "(Central Rear) Interlock轴差";
CM_ SG_ 2566844705 CruiseControlEnableSwitch "巡航开启开关";
CM_ SG_ 2566844705 ASLDEnableSwitch "LIM开关";
CM_ SG_ 2566844705 CruiseOFFswitch "巡航关闭开关（预留）";
CM_ SG_ 2566844705 CruiseDeaccelerateSwitch "巡航复位开关";
CM_ SG_ 2566844705 CruiseResumeSwitch "巡航复位开关";
CM_ SG_ 2566844705 CruiseAccelerateSwitch "巡航加速开关";
CM_ SG_ 2566844705 CruiseControlpauseOrcancelSwitch "CAN按键";
CM_ SG_ 2566844705 PTOstate "PTO state";
CM_ SG_ 2566844705 PTOApplicationMode "PTO  Mode";
CM_ SG_ 2566799393 VehicleHorn "电喇叭状态";
CM_ SG_ 2566799393 TractorRightTurnLightSts "主车右转向灯状态";
CM_ SG_ 2566799393 TractorLeftTurnLightSts "主车左转向灯状态";
CM_ SG_ 2566799393 TractorMarkerLighStst "小灯状态";
CM_ SG_ 2566799393 RearFogLights "后雾灯";
CM_ SG_ 2566799393 TrailerLeftTurnLightSts "挂车左转向灯状态";
CM_ SG_ 2566799393 TrailerRightTurnLightSts "挂车右转向灯状态";
CM_ SG_ 2566799393 TractorMarkerLighOpenWaring "小灯未关提醒";
CM_ SG_ 2566799393 FrontFogLights "前雾灯";
CM_ SG_ 2365443105 HazardLightSwitchSignal "报警灯开关信号";
CM_ SG_ 2365443105 MainSwitch "大灯开关信号";
CM_ SG_ 2365443105 WiperMotorGear "雨刮电机档位";
CM_ SG_ 2365443105 HighBeamSwitchStatus "远光灯开关状态";
CM_ SG_ 2365443105 OvertakingSwitchStatus "超车开关状态";
CM_ SG_ 2365443105 HighLowBeamStatus "远光灯或近光灯选择(远光灯状态)";
CM_ SG_ 2365443105 WiperActive "雨刮状态(自动雨刮控制状态表示)";
CM_ SG_ 2365443105 LowBeamStatus "近光灯状态";
CM_ SG_ 2365443105 TurnSignalSwitch "转向开关信号";
CM_ SG_ 2348875809 ReverseGear "倒档开关";
CM_ SG_ 2348875809 RearviewMirrorHeating "后视镜加热状态";
CM_ SG_ 2566870305 BremsomatSwitch "恒速档开关";
CM_ SG_ 2566870305 Hand_Lever_Signals "手柄档位信号";
CM_ SG_ 2566870305 BremsomatConfiguration "恒速档配置信息";
CM_ SG_ 2566870305 HandLeverConfiguration "手柄档位配置信息";
CM_ SG_ 2566870305 NumberofBrakeSteps "制动档位数量";
CM_ SG_ 2563768353 SwitBackLlluminatBrightPercent "开关光照亮度百分比 ";
CM_ SG_ 2566722849 FlagSetWhenBMSHealthy "Flag set when BMS is healthy BMS通信是否正常，与BMS功能无关";
CM_ SG_ 2566722849 TargetBatteryStateCharge "Target Battery State of Charge SOC目标值，骆驼建议95%，12月8号骆驼来JMC时给的数据。";
CM_ SG_ 2566722849 FlagSetWhenRegenerativeChargingA "Flag set when regenerative  charging mode is allowable  未知";
CM_ SG_ 2566722849 BatteryCurrentMeasured "Battery current measured  IBS测出来的电流值";
CM_ SG_ 2566722849 FlagSetWhenDischargingAllowable "Flag set when battery discharge is allowable 由JMC和电池厂家提供 ";
CM_ SG_ 2566722849 ChargeMode "Charge Mode
可以一直发Mode0，应该是发电机的工作模式不由BCM控制，";
CM_ SG_ 2566722849 MeasuredBatteryVoltage "Measured Battery VoltageIBS测出来的电压值";
CM_ SG_ 2566722849 MeasuredBatteryStateCharge "Measured Battery State of Charge IBS测出来的SOC值";
CM_ SG_ 2566722593 Z_curveBaseBatteryVoltSetpoint "Z-curve based Battery Voltage Setpoint由电池供应商提供";
CM_ SG_ 2566722593 TargetBatteryDischargeVoltage "Target battery discharge Voltage系统最低工作电压，整车提供";
CM_ SG_ 2566722593 TargetBatteryMaxchargeVoltage "Target battery maxcharge Voltage  最大充电电压，骆驼给出最大值28.8V";
CM_ SG_ 2566722593 BatteryLow "电池电量低提示";
CM_ SG_ 2566860833 SOH "State of Health, age of battery电池健康状态百分比";
CM_ SG_ 2566860833 SOHStatus "SOH健康状态";
CM_ SG_ 2566909985 BCM_NM_DA "BCM网络管理报文目的地址";
CM_ SG_ 2566909985 BCM_NM_Limphome "Limphome类型网络管理报文";
CM_ SG_ 2566909985 BCM_NM_Sleep_Ind "睡眠指示";
CM_ SG_ 2566909985 BCM_NM_Sleep_Ack "睡眠应答";
CM_ SG_ 2566909985 BCM_NM_Alive "Alive类型网络管理报文";
CM_ SG_ 2566909985 BCM_NM_Ring "Ring类型网络管理报文";
CM_ SG_ 2564816929 ParticulatetrapregenerationInhib "再生抑制开关";
CM_ SG_ 2564816929 ParticulatetrapregenerationForce "微粒过滤器再生力（手动回复）开关";
CM_ SG_ 2566803745 BCM_ACCusagedemand "驾驶员激活需求";
CM_ SG_ 2566803745 BCM_RequestedACCDistanceMode "距离设置";
CM_ SG_ 2349541921 BCM_AEBS2_EnableSwitch "Driver activation demand for Advanced Emergency Braking System
AEBS使能开关";
CM_ BO_ 2566834721 "默认发送数据见诊断规范定义,当数据场长度大于8个字节时按照J1939 TP层多包传输协议定义进行发送 DM1CLuster_BAM 0x1CECFF21   DM1CLuster_PACKET 0x1CEBFF21";
CM_ SG_ 2431649768 LaneDepartureImminentRightSide "车道即将驶离，右侧 ";
CM_ SG_ 2431649768 OpticalWarningRightSide "右侧光学警告（驾驶员警戒报警）";
CM_ SG_ 2431649768 OpticalWarningLeftSide "左侧光学警告";
CM_ SG_ 2431649768 LaneDepartureImminentLeftSide "车道即将驶离，左侧 ";
CM_ SG_ 2431649768 AcousticalWarningRightSide "右侧声音报警";
CM_ SG_ 2431649768 AcousticalWarningLeftSide "左侧声音报警";
CM_ SG_ 2566806504 IHC_State "自动远近光开关状态";
CM_ SG_ 2566806504 IHC_Mainbeam_Request "自动远近光开关请求";
CM_ SG_ 2566806504 LaneTrackingStatusRightSide "车道跟踪状态右侧 ";
CM_ SG_ 2566806504 LDWSSwitch "LDWS开关状态";
CM_ SG_ 2566806504 LDW_Sensitivity1 "LDW敏感级别";
CM_ SG_ 2566806504 TSR_State "交通限速标指提醒状态";
CM_ SG_ 2566806504 LaneTrackingStatusLeftSide "车道跟踪状态左侧 ";
CM_ SG_ 2566806504 TSR_Targetspeed_Request "交通限速标指提醒目标速度请求（摄像头识别到的车速限制标志指示的车速）";
CM_ SG_ 2566806504 LDW_State "车道偏离状态";
CM_ SG_ 2566806504 Camer_State "摄像头状态";
CM_ SG_ 2566806504 LaneDepartIndicationEnableSta "车道偏离指示启用状态 ";
CM_ BO_ 2566834920 "默认发送数据见诊断规范定义,当数据场长度大于8个字节时按照J1939 TP层多包传输协议定义进行发送 DM1CLuster_BAM 0x1CECFFE8 DM1CLuster_PACKET 0x1CEBFFE8";
CM_ BO_ 2632777704 "CAM_DM1CLuster多包传输的时候发";
CM_ BO_ 2632712168 "CAM_DM1CLuster多包传输的时候发";
CM_ SG_ 2432593706 SpeOfForVehicle "AdaptiveCruiseControlSetDistance mode（Speed of forward vehicle）";
CM_ SG_ 2432593706 AdaCruiseCrlSetSpeed "Value of the desired (chosen) velocity of the adaptive cruise control system.（Adaptive Cruise Control Set Speed）";
CM_ SG_ 2432593706 AdapCruiseCtrlMode "This parameter is used to indicate the current state, or mode, of operation by the Adaptive Cruise Control (ACC) device. The states characterize independent system states (e.g., it is not possible to express distance control active and overtake mode simultaneously). ACC must not switch itself off while active because the driver expects it to work. So if an error occurs, the ACC must signal that to the driver so that the driver knows that he has to switch off the ACC.(Adaptive Cruise Control Mode)

";
CM_ SG_ 2432593706 AdaptiveCruiseCtrlSetDistanceMod "Selected distance mode for adaptive cruise control. ";
CM_ SG_ 2432593706 RoadCurvature "Estimated value of the current road curvature for use by the adaptive cruise control system.  Positive values are used for left curves.  Curvature is the inverse of the radius and is zero for straight roads.";
CM_ SG_ 2432593706 ACCTargetDetected "Signal to indicate to the driver that the ACC system has detected a target. 
";
CM_ SG_ 2432593706 ACCShutoffWarn "Signal to warn the driver of system deactivation due to non-driver actions. Example: Attempting to control vehicle speed below or above limits of ACC. This signal may be used to activate warning sounds or indicators.(ACC System Shutoff Warning)
";
CM_ SG_ 2432593706 ACCDistanceAlertSignal "Signal to indicate to the operator that the ACC system is not able to maintain the distance to the target. Example: Target stopping rapidly. This signal may be used to activate warning sounds or indicators.
";
CM_ SG_ 2432593706 ForwardCollisionWarning "This parameter indicates if a collision is imminent and strong driver reaction either by braking hard or by an avoidance maneuver are imperative to prevent a collision.  
";
CM_ SG_ 2432593706 DisToForVehicle "Distance to the preceding vehicle situated within 250 m in the same lane and moving in the same direction.（Distance to forward vehicle）";
CM_ SG_ 2364550954 AdvancedEmergencyBrakingSystemSt "提前紧急制动系统状态()";
CM_ SG_ 2364550954 Bendoffprobabilityofrelevantobje "相关物体转弯可能性";
CM_ SG_ 2364550954 Timetocollisionwithrelevantobjec "碰撞预计时间";
CM_ SG_ 2364550954 Collisionwarninglevel "碰撞预警等级";
CM_ SG_ 2364550954 FCW_Sensitivity1 "前车碰撞报警敏感级别";
CM_ SG_ 2364550954 Relevantobjectdetectedforadvance "AEB系统是否在监控相关物体";
CM_ BO_ 2566906619 "借用中期（SPN码没有）";
CM_ SG_ 2566906619 RemoteLockorUnlock "遥控解闭锁信号";
CM_ SG_ 2566906619 RemoteHornAlarm "遥控喇叭报警";
CM_ SG_ 2566906619 RemoteLampFlash "遥控灯光闪烁";
CM_ SG_ 2566906875 VINStateResponse "VIN的状态响应 ";
CM_ SG_ 2566906875 LoanState "贷款状态 ";
CM_ SG_ 2566842107 Seconds1 "秒";
CM_ SG_ 2566842107 Hours1 "小时";
CM_ SG_ 2566842107 Month1 "月";
CM_ SG_ 2566842107 Day1 "天";
CM_ SG_ 2566842107 Year1 "年";
CM_ SG_ 2566842107 LocalMinuteOffset1 "分钟偏移";
CM_ SG_ 2566842107 LocalHourOffset1 "小时偏移";
CM_ SG_ 2566842107 Minutes1 "分钟";
CM_ BO_ 2566845491 "借用中期（SPN码没有）";
CM_ SG_ 2566845491 Tire_Location1 "方位";
CM_ SG_ 2566845491 Tire_temperature "温度";
CM_ SG_ 2566845491 SensorStatus "传感器状态";
CM_ SG_ 2566845491 TireAirLeakageRate "轮胎漏气率";
CM_ SG_ 2566845491 TireAirLeakageStatus "轮胎漏气状态 ";
CM_ SG_ 2566845491 VehicleLocation "车辆(预留) ";
CM_ SG_ 2566845491 TireTempThresholdDetection "轮胎温度报警检测 ";
CM_ SG_ 2566845491 TirePressureThresholdDetection "轮胎压力报警检测 ";
CM_ SG_ 2566845491 Tire_Pressure "压力";
CM_ BO_ 2566764851 "借用中期（SPN码没有）";
CM_ SG_ 2566764851 Tire_Location2 "方位";
CM_ SG_ 2566764851 ReferenceTire_temperature "温度(不支持)";
CM_ SG_ 2566764851 ReferenceTireSettingASK "参考轮胎设置询问 ";
CM_ SG_ 2566764851 ReferenceTire_Pressure "压力(不支持)";
CM_ BO_ 2566834739 "默认发送数据见诊断规范定义,当数据场长度大于8个字节时按照J1939 TP层多包传输协议定义进行发送 DM1CLuster_BAM 0x1CECFF33 DM1CLuster_PACKET 0x1CEBFF33";
CM_ SG_ 2365479471 NominalLevelFrontAxle "前轴工作状态等级";
CM_ SG_ 2365479471 BelowNominalLevelRearAxle "后轴重量低于 Nominal level ";
CM_ SG_ 2365479471 AboveNominalLevelFrontAxle "前轴重量高于 Nominal level ";
CM_ SG_ 2365479471 AboveNominalLevelRearAxle "后轴重量高于 Nominal level ";
CM_ SG_ 2365479471 LoweringControlModeFrontAxle "前轴降低控制状态";
CM_ SG_ 2365479471 LoweringControlModeRearAxle "后轴降低控制状态";
CM_ SG_ 2365479471 LiftingControlModeFrontAxle "前轴增加控制状态";
CM_ SG_ 2365479471 LiftingControlModeRearAxle "后轴增加控制状态";
CM_ SG_ 2365479471 LevelControlMode "控制等级状态";
CM_ SG_ 2365479471 LiftAxle1Position "Lift axle 1 position";
CM_ SG_ 2365479471 NominallevelFrontAxle "后轴工作状态等级";
CM_ SG_ 2365479471 FrontAxleInBumperRange "Front axle in bumper range";
CM_ SG_ 2365479471 RearAxleInBumperRange "Rear axle in bumper range";
CM_ SG_ 2365479471 SuspensionRemoteControl_1 "Suspension Remote control #1";
CM_ SG_ 2365479471 SuspensionControlRefusalInformat "Suspension control refusal information";
CM_ SG_ 2365479471 BelowNominalLevelFrontAxle "前轴重量低于 Nominal level ";
CM_ SG_ 2566805807 Relativelevelfrontaxleleft "Relative level front axle left";
CM_ SG_ 2566805807 Relativelevelfrontaxleright "Relative level front axle right";
CM_ SG_ 2566805807 Relativelevelrearaxleleft "Relative level rear axle left";
CM_ SG_ 2566805807 Relativelevelrearaxleright "Relative level rear axle right";
CM_ SG_ 2566805551 Bellowpressurefrontaxleleft "Bellow pressure front axle left";
CM_ SG_ 2566805551 Bellowpressurefrontaxleright "Bellow pressure front axle right";
CM_ SG_ 2566805551 Bellowpressurerearaxleleft "Bellow pressure rear axle left";
CM_ SG_ 2566805551 Bellowpressurerearaxleright "Bellow pressure rear axle right";
CM_ SG_ 2566882563 STOPrequested "红灯故障";
CM_ SG_ 2566882563 ClutchOverload "离合过载";
CM_ SG_ 2566882563 LowAirPressure "气压低（气动的 ）";
CM_ SG_ 2566882563 TemperatureTooHigh "温度过高，变速箱温度";
CM_ SG_ 2566882563 CheckPhase "刚上电自检过程";
CM_ SG_ 2566882563 ReleaseAcceleratorPedal "松开油门踏板提醒";
CM_ SG_ 2566882563 WorkshopRequestedOrSpannerWarnin "黄灯故障";
CM_ SG_ 2566882563 PutLeverToNeutral "把手柄回到空挡位置提醒";
CM_ SG_ 2566882563 PressBrakePedal "踩下制动踏板";
CM_ SG_ 2566882563 PTO1Active "PTO1使能";
CM_ SG_ 2566882563 PTO2Active "PTO2使能";
CM_ SG_ 2566882563 ManoeuvringMode "半离合模式（仪表显示档位）";
CM_ SG_ 2566882563 AutomaticMode "（自动模式）";
CM_ SG_ 2566882563 ClutchWear "离合磨损";
CM_ BO_ 2566801923 "请求发动机启动";
CM_ SG_ 2566801923 TransmissionEngineCrankEnable "发动机能否启动";
CM_ SG_ 2566801923 TransmissionMode4indicator "传输模式4指示器";
CM_ SG_ 2566801923 TransmissionMode3indicator "传输模式3指示器";
CM_ SG_ 2566801923 TransmissionMode2indicator "传输模式2指示器";
CM_ SG_ 2566801923 TransmissionMode1indicator "传输模式1指示器";
CM_ BO_ 2566834691 "默认发送数据见诊断规范定义,当数据场长度大于8个字节时按照J1939 TP层多包传输协议定义进行发送 DM1CLuster_BAM 0x1CECFF03   DM1CLuster_PACKET 0x1CEBFF03";
CM_ BO_ 2632777475 "TCM_DM1CLuster多包传输的时候发";
CM_ BO_ 2632711939 "TCM_DM1CLuster多包传输的时候发";
CM_ BO_ 2566834735 "默认发送数据见诊断规范定义,当数据场长度大于8个字节时按照J1939 TP层多包传输协议定义进行发送 DM1CLuster_BAM 0x1CECFF2F   DM1CLuster_PACKET 0x1CEBFF2F";
CM_ SG_ 2566834735 AmberWarningLampStatus "环境警告灯状态";
CM_ BO_ 2632777519 "ECAS_DM1CLuster多包传输的时候发";
CM_ BO_ 2632711983 "ECAS_DM1CLuster多包传输的时候发";
CM_ SG_ 2566901812 PEPS_RkeCmd "RKE命令";
CM_ SG_ 2566901812 PEPS_TrunkSwPress_Resvered "Trunk Micro Switch Pressed Signal (Only Used to Wake Up BCM)
行李箱微动开关信号（用于唤醒BCM）当前有网络管理，BCM不需要对其进行处理(预留)";
CM_ SG_ 2566901812 PEPS_BCMAlarm "Alarm PEPS Send to BCM
PEPS发送BCM报警信号";
CM_ SG_ 2566901812 PEPS_ICAlarm "Alarm PEPS Send to IC
PEPS发送IC报警信号";
CM_ SG_ 2566901812 PEPS_ICInd "Indicate PEPS Send to IC
PEPS发送ICM指示信号";
CM_ SG_ 2566901812 PEPS_CurPMM "当前电源管理模式";
CM_ SG_ 2566901812 PEPS_ACC_PROStat "电源ACC继电器驱动输出状态";
CM_ SG_ 2566901812 PEPS_IGN1_PROStat "电源IGN1继电器驱动输出状态";
CM_ SG_ 2566901812 PEPS_PkeCmd_Resvered "PKE命令(预留)";
CM_ SG_ 2566901812 PEPS_IGN2_PROStat "电源IGN2继电器驱动输出状态";
CM_ SG_ 2566901812 PEPS_ST_PROStat_Resv "电源ST继电器驱动输出状态(预留)";
CM_ SG_ 2566901812 PEPS_SystemPowerMode "PEPS系统电源状态";
CM_ SG_ 2566901812 PEPS_MessageType "与EMS通信命令类型";
CM_ SG_ 2566901812 PEPS_FRSwPress_Resvered "Front Right Micro Switch Pressed Signal (Only Used to Wake Up BCM)
右前微动开关信号（用于唤醒BCM）当前有网络管理，BCM不需要对其进行处理(预留)";
CM_ SG_ 2566901812 PEPS_FLSwPress_Resvered "Front Left Micro Switch Pressed Signal (Only Used to Wake Up BCM)
左前微动开关信号（用于唤醒BCM）当前有网络管理，BCM不需要对其进行处理(预留)";
CM_ SG_ 2566902068 PEPS_EncryptedRsvd "PEPS响应EMS认证保留字节";
CM_ SG_ 2566902068 PEPS_EncryptedResponseByte0 "PEPS响应EMS认证加密数据(低位)";
CM_ SG_ 2566902068 PEPS_EncryptedResponseByte1 "PEPS响应EMS认证加密数据";
CM_ SG_ 2566902068 PEPS_EncryptedResponseByte2 "PEPS响应EMS认证加密数据";
CM_ SG_ 2566902068 PEPS_EncryptedResponseByte3 "PEPS响应EMS认证加密数据";
CM_ SG_ 2566902068 PEPS_EncryptedResponseByte4 "PEPS响应EMS认证加密数据";
CM_ SG_ 2566902068 PEPS_EncryptedResponseByte5 "PEPS响应EMS认证加密数据(高位)";
CM_ SG_ 2566902068 PEPS_EncryptedStatus "PEPS响应EMS认证状态";
CM_ BO_ 2566834740 "默认发送数据见诊断规范定义,当数据场长度大于8个字节时按照J1939 TP层多包传输协议定义进行发送 DM1CLuster_BAM 0x1CECFF34   DM1CLuster_PACKET 0x1CEBFF34";
CM_ BO_ 2632777524 "IMMO_DM1CLuster多包传输的时候发";
CM_ BO_ 2632711988 "IMMO_DM1CLuster多包传输的时候发";
CM_ BO_ 2566834943 "默认发送数据见诊断规范定义,当数据场长度大于8个字节时按照J1939 TP层多包传输协议定义进行发送 DM1CLuster_BAM 0x1CECFF34   DM1CLuster_PACKET 0x1CEBFF34";
CM_ SG_ 2566910004 PEPS_NM_DA "PEPS网络管理报文目的地址";
CM_ SG_ 2566910004 PEPS_NM_Limphome "Limphome类型网络管理报文";
CM_ SG_ 2566910004 PEPS_NM_Sleep_Ind "睡眠指示";
CM_ SG_ 2566910004 PEPS_NM_Sleep_Ack "睡眠应答";
CM_ SG_ 2566910004 PEPS_NM_Alive "Alive类型网络管理报文";
CM_ SG_ 2566910004 PEPS_NM_Ring "Ring类型网络管理报文";
CM_ SG_ 2566783796 ESCLCommand "ESCLCommand";
CM_ SG_ 2566783796 PowerMode "PowerMode";
CM_ SG_ 2566783796 PSAliveCounter "PSAliveCounter";
CM_ SG_ 2566783796 PS_CRC "PS_CRC";
CM_ BO_ 2564640052 "PS_ESCL_ATR (ESCL Anti-theft Request)";
CM_ SG_ 2564640052 Anti_theftEncryptionIndicatorSta "Anti-theftEncryptionIndicatorStates/防盗加密信号状态";
CM_ SG_ 2564640052 Anti_theftDesiredExitModeStates "Anti-theftDesiredExitModeStates/防盗退出模式状态";
CM_ SG_ 2564640052 Anti_theftCommandStates "Anti-theftCommandStates/防盗命令状态";
CM_ SG_ 2564640052 Anti_theftPasswordRepresentation "Anti-theftPasswordRepresentation/防盗许可准备";
CM_ SG_ 2565865488 RetarderTorqueMode1 "（Byte1=0001，Byte2<7d，Byte4.bit1~bit2=00，点亮指示灯3s。工作灯：Byte1.1~1.4非0，且byte2＜0x7D，且4.1~4.2为00b，工作指示灯长亮。超温降扭：当Byte1=1000，Byte2<0x7D 、Byte4.bit1~bit2=01时, 缓速器工作指示灯闪烁。超温退出：当Byte1=1000、Byte2=0x7D 、Byte4.bit1~bit2=01时, 缓速器超温退出。制动灯：当Byte1=0001、1000、1010，Byte2<0x7D时，制动灯点亮（或Byte4.bit3~bit4=00b，不点）";
CM_ SG_ 2565865488 EngineCoolantLoadIncrease1 "EngineCoolantLoadIncrease1";
CM_ SG_ 2565865488 RetarderRequestingBrakeLight1 "BCM点亮制动灯";
CM_ SG_ 2565865488 SourceAddressControllingDeviceFo "Source Address of controlling device for retarder control";
CM_ SG_ 2565865488 DriversDemandRetarderPercentTorq "Drivers demand retarder - percent torque";
CM_ SG_ 2565865488 RetarderSelectionNon_engine "Retarder selection, non-engine";
CM_ SG_ 2565865488 ActualMaximumAvailableRetarderPe "Actual maximum available retarder - percent torque";
CM_ SG_ 2565865488 ActualRetarderPercentTorque1 "实际扭矩";
CM_ BO_ 2566852624 "FAST自定义报文";
CM_ SG_ 2566852624 WaterTemp "水温";
CM_ SG_ 2566852624 RetarderManualShift "缓速器手动档位";
CM_ SG_ 2566852624 OIlTemp "油温";
CM_ BO_ 2566834704 "默认发送数据见诊断规范定义,当数据场长度大于8个字节时按照J1939 TP层多包传输协议定义进行发送 DM1CLuster_BAM 0x1CECFF10   DM1CLuster_PACKET 0x1CEBFF10";
CM_ BO_ 2632777488 "RCM_DM1CLuster多包传输的时候发";
CM_ BO_ 2632711952 "RCM_DM1CLuster多包传输的时候发";
CM_ SG_ 2566905966 SYSDisplayRequest "系统显示请求";
CM_ SG_ 2566905966 WORKStatus "工作状态";
CM_ SG_ 2566905966 PedestrianRecognition "行人识别功能开关";
CM_ SG_ 2566905966 TargetDetection "目标物检测";
CM_ SG_ 2566905966 TargetDistanceLevel "目标物距离等级";
CM_ SG_ 2566905966 TargetDetectionAlarm "目标物检测报警信号";
CM_ SG_ 2566905966 TargetDistance "目标物距离";
CM_ BO_ 2566834798 "默认发送数据见诊断规范定义,当数据场长度大于8个字节时按照J1939 TP层多包传输协议定义进行发送 DM1CLuster_BAM 0x1CECFF6E DM1CLuster_PACKET 0x1CEBFF6E";
CM_ SG_ 2566908272 Radar_Warning_Left "左雷达报警信号Left Radar waring";
CM_ SG_ 2566908272 Radar_SystemError_Left "左雷达系统错误Indicates the system error of Left Radar";
CM_ SG_ 2566908272 Radar_Status_Left "左雷达使能状态Indicates the status of Left Radar";
CM_ BO_ 2566834800 "默认发送数据见诊断规范定义,当数据场长度大于8个字节时按照J1939 TP层多包传输协议定义进行发送 DM1CLuster_BAM 0x1CECFF70  DM1CLuster_PACKET 0x1CEBFF70";
CM_ BO_ 2632777584 "BSDL_DM1Cluster多包传输的时候发";
CM_ BO_ 2632712048 "BSDL_DM1Cluster多包传输的时候发";
CM_ SG_ 2566908273 Radar_Warning_Right "右雷达报警信号Right Radar waring";
CM_ SG_ 2566908273 Radar_SystemError_Right "右雷达系统错误Indicates the system error of Right Radar";
CM_ SG_ 2566908273 Radar_Status_Right "右雷达使能状态Indicates the status of Right Radar";
CM_ BO_ 2566834801 "默认发送数据见诊断规范定义,当数据场长度大于8个字节时按照J1939 TP层多包传输协议定义进行发送 DM1CLuster_BAM 0x1CECFF71 DM1CLuster_PACKET 0x1CEBFF71";
CM_ BO_ 2632777585 "BSDR_DM1Cluster多包传输的时候发";
CM_ BO_ 2632712049 "BSDR_DM1Cluster多包传输的时候发";
CM_ SG_ 2564568141 Anti_theftEncryptionSeedPresentI "Anti-theft Encryption Seed Present Indicator";
CM_ SG_ 2564568141 Anti_theftPasswordValidIndicator "Anti-theft Password Valid Indicator";
CM_ SG_ 2564568141 Anti_theftComponentStatusStates "Anti-theft Component Status States";
CM_ SG_ 2564568141 Anti_theftModifyPasswordStates "Anti-theft Modify Password States";
CM_ SG_ 2564568141 Anti_theftRandomNumber "Anti-theft Random Number";
CM_ SG_ 2566784333 UnlockingRunning "解锁运行";
CM_ SG_ 2566784333 ESCLAliveCounter "ESCLAliveCounter";
CM_ SG_ 2566784333 ESCL_CRC "ESCL_CRC";
CM_ SG_ 2566784333 ESCLUnlockSensorsSts "解锁传感器位置状态";
CM_ SG_ 2566784333 ESCLLockSensorSts "闭锁传感器位置状态";
CM_ SG_ 2566784333 LockingRunning "闭锁运行";
CM_ BO_ 2566834765 "默认发送数据见诊断规范定义,当数据场长度大于8个字节时按照J1939 TP层多包传输协议定义进行发送 DM1CLuster_BAM 0x1CECFF4D DM1CLuster_PACKET 0x1CEBFF4D";
CM_ SG_ 2565866755 SelectedGear "选择档位";
CM_ SG_ 2565866755 CurrentGear "当前档位";
CM_ SG_ 2565866755 ActualGearRatio "速比";
CM_ SG_ 2566845555 Tire_Location_TESD "方位";
CM_ SG_ 2566845555 Tire_temperature_TESD "温度";
CM_ SG_ 2566845555 CTIWheelEndElectricalFault "收不到轮胎信号报警";
CM_ SG_ 2566845555 CTITireStatus "轮胎漏气报警";
CM_ SG_ 2566845555 Tire_Pressure_TESD "压力";
CM_ BO_ 2566834803 "默认发送数据见诊断规范定义,当数据场长度大于8个字节时按照J1939 TP层多包传输协议定义进行发送 DM1CLuster_BAM 0x1CECFF73  DM1CLuster_PACKET 0x1CEBFF73";
CM_ BO_ 2632777587 "TESD_DM1CLuster多包传输的时候发";
CM_ BO_ 2632712051 "TESD_DM1CLuster多包传输的时候发";
CM_ BO_ 2566834725 "默认发送数据见诊断规范定义,当数据场长度大于8个字节时按照J1939 TP层多包传输协议定义进行发送 DM1CLuster_BAM 0x1CECFF25 DM1CLuster_PACKET 0x1CEBFF25";
CM_ BO_ 2564432369 "Diagnostic Physical Request Frame to BCM";
CM_ BO_ 2564436977 "Diagnostic Physical Request Frame to TPMS";
CM_ BO_ 2564489201 "Diagnostic Physical Request Frame to PEPS";
CM_ BO_ 2564429809 "Diagnostic Physical Request Frame to IC";
CM_ BO_ 2564443377 "Diagnostic Physical Request Frame to MP5";
CM_ BO_ 2564483057 "Diagnostic Physical Request Frame to DDWS";
CM_ BO_ 2564452081 "Diagnostic Physical Request Frame to NV";
CM_ BO_ 2564430321 "Diagnostic Physical Request Frame to EATC";
CM_ BO_ 2564484849 "Diagnostic Physical Request Frame to TAC";
CM_ BO_ 2564443633 "Diagnostic Physical Request Frame to ESCL";
CM_ BO_ 2564485409 "Diagnostic Response Frame From BCM";
CM_ BO_ 2564485427 "Diagnostic Response Frame From TPMS";
CM_ BO_ 2564485428 "Diagnostic Response Frame From PEPS";
CM_ BO_ 2564485399 "Diagnostic Response Frame From IC";
CM_ BO_ 2564485452 "Diagnostic Response Frame From MP5";
CM_ BO_ 2564485607 "Diagnostic Response Frame From DDWS";
CM_ BO_ 2564485486 "Diagnostic Response Frame From NV";
CM_ BO_ 2564485401 "Diagnostic Response Frame From EATC";
CM_ BO_ 2564485614 "Diagnostic Response Frame From TAC";
CM_ BO_ 2564485453 "Diagnostic Response Frame From ESCL";
CM_ BO_ 2564554737 "Diagnostic Functional Request Frame";
CM_ BO_ 2564502513 "Diagnostic Functional Request Frame";
BA_DEF_ BO_  "NmMessage" ENUM  "No","Yes";
BA_DEF_ BO_  "DiagState" ENUM  "No","Yes";
BA_DEF_ BO_  "DiagResponse" ENUM  "No","Yes";
BA_DEF_ BO_  "GenMsgSendType" ENUM  "Cycle","NoSendType","IfActive","OnRequest";
BA_DEF_ BO_  "GenMsgCycleTime" INT 0 0;
BA_DEF_ SG_  "GenSigSendType" ENUM  "Cycle","OnChange","OnWrite","IfActive","OnChangeWithRepetition","OnWriteWithRepetition","IfActiveWithRepetition","NoSendType";
BA_DEF_ SG_  "GenSigStartValue" INT 0 0;
BA_DEF_ BO_  "GenMsgCycleTimeFast" INT 0 0;
BA_DEF_ BO_  "GenMsgNrOfRepetition" INT 0 0;
BA_DEF_ SG_  "SPN" INT 0 0;
BA_DEF_ SG_  "SigType" ENUM  "Default","Range","RangeSigned","ASCII","Discrete","Control","ReferencePGN","DTC","StringDelimiter","StringLength","StringLengthControl";
BA_DEF_ SG_  "GenSigEVName" STRING ;
BA_DEF_ SG_  "GenSigILSupport" ENUM  "Yes","No";
BA_DEF_ BO_  "GenMsgILSupport" ENUM  "Yes","No";
BA_DEF_ BO_  "GenMsgRequestable" INT 0 1;
BA_DEF_ BO_  "VFrameFormat" ENUM  "StandardCAN","ExtendedCAN","reserved","J1939PG";
BA_DEF_ SG_  "SystemSignalLongSymbol" STRING ;
BA_DEF_DEF_  "NmMessage" "No";
BA_DEF_DEF_  "DiagState" "No";
BA_DEF_DEF_  "DiagResponse" "No";
BA_DEF_DEF_  "GenMsgSendType" "Cycle";
BA_DEF_DEF_  "GenMsgCycleTime" 0;
BA_DEF_DEF_  "GenSigSendType" "Cycle";
BA_DEF_DEF_  "GenSigStartValue" 0;
BA_DEF_DEF_  "GenMsgCycleTimeFast" 0;
BA_DEF_DEF_  "GenMsgNrOfRepetition" 0;
BA_DEF_DEF_  "SPN" 0;
BA_DEF_DEF_  "SigType" "Default";
BA_DEF_DEF_  "GenSigEVName" "Env@Nodename_@Signame";
BA_DEF_DEF_  "GenSigILSupport" "Yes";
BA_DEF_DEF_  "GenMsgILSupport" "Yes";
BA_DEF_DEF_  "GenMsgRequestable" 1;
BA_DEF_DEF_  "VFrameFormat" "J1939PG";
BA_DEF_DEF_  "SystemSignalLongSymbol" "";
BA_ "GenMsgCycleTime" BO_ 2566838561 100;
BA_ "GenMsgCycleTime" BO_ 2565867041 500;
BA_ "GenMsgCycleTime" BO_ 2566844705 100;
BA_ "GenMsgCycleTime" BO_ 2566799393 40;
BA_ "GenMsgCycleTime" BO_ 2365443105 100;
BA_ "GenMsgCycleTime" BO_ 2348875809 50;
BA_ "GenMsgCycleTime" BO_ 2566870305 100;
BA_ "GenMsgCycleTime" BO_ 2563768353 100;
BA_ "GenMsgCycleTime" BO_ 2566722849 100;
BA_ "GenMsgCycleTime" BO_ 2566722593 100;
BA_ "GenMsgCycleTime" BO_ 2566860833 1000;
BA_ "GenMsgSendType" BO_ 2566909985 1;
BA_ "NmMessage" BO_ 2566909985 1;
BA_ "GenMsgCycleTime" BO_ 2564816929 1000;
BA_ "GenMsgCycleTime" BO_ 2566803745 250;
BA_ "GenMsgCycleTime" BO_ 2349541921 100;
BA_ "GenMsgCycleTime" BO_ 2566834721 1000;
BA_ "DiagResponse" BO_ 2566834721 1;
BA_ "DiagState" BO_ 2566834721 1;
BA_ "GenMsgCycleTime" BO_ 2431649768 50;
BA_ "GenMsgCycleTime" BO_ 2566806504 100;
BA_ "GenMsgCycleTime" BO_ 2566834920 1000;
BA_ "DiagResponse" BO_ 2566834920 1;
BA_ "DiagState" BO_ 2566834920 1;
BA_ "GenMsgSendType" BO_ 2632777704 1;
BA_ "DiagResponse" BO_ 2632777704 1;
BA_ "DiagState" BO_ 2632777704 1;
BA_ "GenMsgSendType" BO_ 2632712168 1;
BA_ "DiagResponse" BO_ 2632712168 1;
BA_ "DiagState" BO_ 2632712168 1;
BA_ "GenMsgCycleTime" BO_ 2432593706 50;
BA_ "GenMsgCycleTime" BO_ 2364550954 50;
BA_ "GenMsgNrOfRepetition" BO_ 2566906619 3;
BA_ "GenMsgCycleTimeFast" BO_ 2566906619 100;
BA_ "GenMsgSendType" BO_ 2566906619 1;
BA_ "GenMsgSendType" BO_ 2566906875 1;
BA_ "GenMsgCycleTime" BO_ 2566842107 1000;
BA_ "GenMsgCycleTime" BO_ 2566845491 10000;
BA_ "GenMsgCycleTime" BO_ 2566764851 500;
BA_ "GenMsgCycleTime" BO_ 2566834739 1000;
BA_ "DiagResponse" BO_ 2566834739 1;
BA_ "DiagState" BO_ 2566834739 1;
BA_ "GenMsgCycleTime" BO_ 2365479471 100;
BA_ "GenMsgCycleTime" BO_ 2566805807 100;
BA_ "GenMsgCycleTime" BO_ 2566805551 100;
BA_ "GenMsgCycleTime" BO_ 2566882563 100;
BA_ "GenMsgCycleTime" BO_ 2566801923 100;
BA_ "GenMsgCycleTime" BO_ 2566834691 1000;
BA_ "DiagResponse" BO_ 2566834691 1;
BA_ "DiagState" BO_ 2566834691 1;
BA_ "GenMsgSendType" BO_ 2632777475 1;
BA_ "DiagResponse" BO_ 2632777475 1;
BA_ "DiagState" BO_ 2632777475 1;
BA_ "GenMsgSendType" BO_ 2632711939 1;
BA_ "DiagResponse" BO_ 2632711939 1;
BA_ "DiagState" BO_ 2632711939 1;
BA_ "GenMsgCycleTime" BO_ 2566834735 1000;
BA_ "DiagResponse" BO_ 2566834735 1;
BA_ "DiagState" BO_ 2566834735 1;
BA_ "GenMsgSendType" BO_ 2632777519 1;
BA_ "DiagResponse" BO_ 2632777519 1;
BA_ "DiagState" BO_ 2632777519 1;
BA_ "GenMsgSendType" BO_ 2632711983 1;
BA_ "DiagResponse" BO_ 2632711983 1;
BA_ "DiagState" BO_ 2632711983 1;
BA_ "GenMsgNrOfRepetition" BO_ 2566901812 3;
BA_ "GenMsgCycleTimeFast" BO_ 2566901812 20;
BA_ "GenMsgCycleTime" BO_ 2566901812 100;
BA_ "GenMsgSendType" BO_ 2566902068 1;
BA_ "GenMsgCycleTime" BO_ 2566834740 1000;
BA_ "DiagResponse" BO_ 2566834740 1;
BA_ "DiagState" BO_ 2566834740 1;
BA_ "GenMsgSendType" BO_ 2632777524 1;
BA_ "DiagResponse" BO_ 2632777524 1;
BA_ "DiagState" BO_ 2632777524 1;
BA_ "GenMsgSendType" BO_ 2632711988 1;
BA_ "DiagResponse" BO_ 2632711988 1;
BA_ "DiagState" BO_ 2632711988 1;
BA_ "GenMsgCycleTime" BO_ 2566834943 1000;
BA_ "DiagResponse" BO_ 2566834943 1;
BA_ "DiagState" BO_ 2566834943 1;
BA_ "GenMsgSendType" BO_ 2566910004 1;
BA_ "NmMessage" BO_ 2566910004 1;
BA_ "GenMsgCycleTime" BO_ 2566783796 100;
BA_ "GenMsgSendType" BO_ 2564640052 1;
BA_ "GenMsgCycleTime" BO_ 2565865488 100;
BA_ "GenMsgCycleTime" BO_ 2566852624 500;
BA_ "GenMsgCycleTime" BO_ 2566834704 1000;
BA_ "DiagResponse" BO_ 2566834704 1;
BA_ "DiagState" BO_ 2566834704 1;
BA_ "GenMsgSendType" BO_ 2632777488 1;
BA_ "DiagResponse" BO_ 2632777488 1;
BA_ "DiagState" BO_ 2632777488 1;
BA_ "GenMsgSendType" BO_ 2632711952 1;
BA_ "DiagResponse" BO_ 2632711952 1;
BA_ "DiagState" BO_ 2632711952 1;
BA_ "GenMsgCycleTime" BO_ 2566905966 100;
BA_ "GenMsgCycleTime" BO_ 2566834798 1000;
BA_ "DiagResponse" BO_ 2566834798 1;
BA_ "DiagState" BO_ 2566834798 1;
BA_ "GenMsgCycleTime" BO_ 2566908272 50;
BA_ "GenMsgCycleTime" BO_ 2566834800 1000;
BA_ "DiagResponse" BO_ 2566834800 1;
BA_ "DiagState" BO_ 2566834800 1;
BA_ "GenMsgSendType" BO_ 2632777584 1;
BA_ "DiagResponse" BO_ 2632777584 1;
BA_ "DiagState" BO_ 2632777584 1;
BA_ "GenMsgSendType" BO_ 2632712048 1;
BA_ "DiagResponse" BO_ 2632712048 1;
BA_ "DiagState" BO_ 2632712048 1;
BA_ "GenMsgCycleTime" BO_ 2566908273 50;
BA_ "GenMsgCycleTime" BO_ 2566834801 1000;
BA_ "DiagResponse" BO_ 2566834801 1;
BA_ "DiagState" BO_ 2566834801 1;
BA_ "GenMsgSendType" BO_ 2632777585 1;
BA_ "DiagResponse" BO_ 2632777585 1;
BA_ "DiagState" BO_ 2632777585 1;
BA_ "GenMsgSendType" BO_ 2632712049 1;
BA_ "DiagResponse" BO_ 2632712049 1;
BA_ "DiagState" BO_ 2632712049 1;
BA_ "GenMsgSendType" BO_ 2564568141 1;
BA_ "GenMsgCycleTime" BO_ 2566784333 50;
BA_ "GenMsgCycleTime" BO_ 2566834765 1000;
BA_ "DiagResponse" BO_ 2566834765 1;
BA_ "DiagState" BO_ 2566834765 1;
BA_ "GenMsgCycleTime" BO_ 2565866755 100;
BA_ "GenMsgCycleTime" BO_ 2566845555 10000;
BA_ "GenMsgCycleTime" BO_ 2566834803 1000;
BA_ "DiagResponse" BO_ 2566834803 1;
BA_ "DiagState" BO_ 2566834803 1;
BA_ "GenMsgSendType" BO_ 2632777587 1;
BA_ "DiagResponse" BO_ 2632777587 1;
BA_ "DiagState" BO_ 2632777587 1;
BA_ "GenMsgSendType" BO_ 2632712051 1;
BA_ "DiagResponse" BO_ 2632712051 1;
BA_ "DiagState" BO_ 2632712051 1;
BA_ "GenMsgCycleTime" BO_ 2566834725 1000;
BA_ "DiagResponse" BO_ 2566834725 1;
BA_ "DiagState" BO_ 2566834725 1;
BA_ "GenMsgSendType" BO_ 2564432369 1;
BA_ "DiagResponse" BO_ 2564432369 1;
BA_ "DiagState" BO_ 2564432369 1;
BA_ "GenMsgSendType" BO_ 2564436977 1;
BA_ "DiagResponse" BO_ 2564436977 1;
BA_ "DiagState" BO_ 2564436977 1;
BA_ "GenMsgSendType" BO_ 2564489201 1;
BA_ "DiagResponse" BO_ 2564489201 1;
BA_ "DiagState" BO_ 2564489201 1;
BA_ "GenMsgSendType" BO_ 2564429809 1;
BA_ "DiagResponse" BO_ 2564429809 1;
BA_ "DiagState" BO_ 2564429809 1;
BA_ "GenMsgSendType" BO_ 2564443377 1;
BA_ "DiagResponse" BO_ 2564443377 1;
BA_ "DiagState" BO_ 2564443377 1;
BA_ "GenMsgSendType" BO_ 2564483057 1;
BA_ "DiagResponse" BO_ 2564483057 1;
BA_ "DiagState" BO_ 2564483057 1;
BA_ "GenMsgSendType" BO_ 2564452081 1;
BA_ "DiagResponse" BO_ 2564452081 1;
BA_ "DiagState" BO_ 2564452081 1;
BA_ "GenMsgSendType" BO_ 2564430321 1;
BA_ "DiagResponse" BO_ 2564430321 1;
BA_ "DiagState" BO_ 2564430321 1;
BA_ "GenMsgSendType" BO_ 2564484849 1;
BA_ "DiagResponse" BO_ 2564484849 1;
BA_ "DiagState" BO_ 2564484849 1;
BA_ "GenMsgSendType" BO_ 2564443633 1;
BA_ "DiagResponse" BO_ 2564443633 1;
BA_ "DiagState" BO_ 2564443633 1;
BA_ "GenMsgSendType" BO_ 2564485409 1;
BA_ "DiagResponse" BO_ 2564485409 1;
BA_ "DiagState" BO_ 2564485409 1;
BA_ "GenMsgSendType" BO_ 2564485427 1;
BA_ "DiagResponse" BO_ 2564485427 1;
BA_ "DiagState" BO_ 2564485427 1;
BA_ "GenMsgSendType" BO_ 2564485428 1;
BA_ "DiagResponse" BO_ 2564485428 1;
BA_ "DiagState" BO_ 2564485428 1;
BA_ "GenMsgSendType" BO_ 2564485399 1;
BA_ "DiagResponse" BO_ 2564485399 1;
BA_ "DiagState" BO_ 2564485399 1;
BA_ "GenMsgSendType" BO_ 2564485452 1;
BA_ "DiagResponse" BO_ 2564485452 1;
BA_ "DiagState" BO_ 2564485452 1;
BA_ "GenMsgSendType" BO_ 2564485607 1;
BA_ "DiagResponse" BO_ 2564485607 1;
BA_ "DiagState" BO_ 2564485607 1;
BA_ "GenMsgSendType" BO_ 2564485486 1;
BA_ "DiagResponse" BO_ 2564485486 1;
BA_ "DiagState" BO_ 2564485486 1;
BA_ "GenMsgSendType" BO_ 2564485401 1;
BA_ "DiagResponse" BO_ 2564485401 1;
BA_ "DiagState" BO_ 2564485401 1;
BA_ "GenMsgSendType" BO_ 2564485614 1;
BA_ "DiagResponse" BO_ 2564485614 1;
BA_ "DiagState" BO_ 2564485614 1;
BA_ "GenMsgSendType" BO_ 2564485453 1;
BA_ "DiagResponse" BO_ 2564485453 1;
BA_ "DiagState" BO_ 2564485453 1;
BA_ "GenMsgSendType" BO_ 2564554737 1;
BA_ "DiagResponse" BO_ 2564554737 1;
BA_ "DiagState" BO_ 2564554737 1;
BA_ "GenMsgSendType" BO_ 2564502513 1;
BA_ "DiagResponse" BO_ 2564502513 1;
BA_ "DiagState" BO_ 2564502513 1;
BA_ "GenMsgCycleTime" BO_ 2566909989 100;
BA_ "NmMessage" BO_ 2566909989 1;
BA_ "SPN" SG_ 2566838561 Passenger_Door_Status 704;
BA_ "SPN" SG_ 2566838561 Current_Power_Supply_Status 705;
BA_ "SPN" SG_ 2566838561 Driver_Door_Status 703;
BA_ "SPN" SG_ 2566838561 Door_Locked_Status 705;
BA_ "SPN" SG_ 2565867041 RearAxle1 570;
BA_ "SPN" SG_ 2565867041 RearAxle2 569;
BA_ "SPN" SG_ 2565867041 Interlock 566;
BA_ "SPN" SG_ 2566844705 CruiseControlEnableSwitch 596;
BA_ "SPN" SG_ 2566844705 ASLDEnableSwitch 520721;
BA_ "SPN" SG_ 2566844705 CruiseOFFswitch 599;
BA_ "SPN" SG_ 2566844705 CruiseDeaccelerateSwitch 600;
BA_ "SPN" SG_ 2566844705 CruiseResumeSwitch 601;
BA_ "SPN" SG_ 2566844705 CruiseAccelerateSwitch 602;
BA_ "SPN" SG_ 2566844705 PTOstate 976;
BA_ "SPN" SG_ 2566799393 VehicleHorn 2386;
BA_ "SPN" SG_ 2566799393 TractorRightTurnLightSts 2370;
BA_ "SPN" SG_ 2566799393 TractorLeftTurnLightSts 2368;
BA_ "SPN" SG_ 2566799393 TractorMarkerLighStst 2378;
BA_ "SPN" SG_ 2566799393 RearFogLights 2390;
BA_ "SPN" SG_ 2566799393 TrailerLeftTurnLightSts 2398;
BA_ "SPN" SG_ 2566799393 TrailerRightTurnLightSts 2396;
BA_ "SPN" SG_ 2566799393 TractorMarkerLighOpenWaring 520715;
BA_ "SPN" SG_ 2566799393 FrontFogLights 2388;
BA_ "SPN" SG_ 2365443105 HazardLightSwitchSignal 2875;
BA_ "SPN" SG_ 2365443105 MainSwitch 2872;
BA_ "SPN" SG_ 2365443105 WiperMotorGear 520716;
BA_ "GenSigStartValue" SG_ 2365443105 WiperMotorGear 1;
BA_ "SPN" SG_ 2365443105 HighBeamSwitchStatus 520717;
BA_ "SPN" SG_ 2365443105 OvertakingSwitchStatus 520718;
BA_ "SPN" SG_ 2365443105 HighLowBeamStatus 520705;
BA_ "SPN" SG_ 2365443105 WiperActive 520704;
BA_ "SPN" SG_ 2365443105 LowBeamStatus 2350;
BA_ "SPN" SG_ 2365443105 TurnSignalSwitch 2876;
BA_ "SPN" SG_ 2348875809 ReverseGear 525;
BA_ "SPN" SG_ 2348875809 RearviewMirrorHeating 520707;
BA_ "GenSigStartValue" SG_ 2566870305 Hand_Lever_Signals 1;
BA_ "GenSigStartValue" SG_ 2566870305 BremsomatConfiguration 1;
BA_ "GenSigStartValue" SG_ 2566870305 HandLeverConfiguration 1;
BA_ "GenSigStartValue" SG_ 2566870305 NumberofBrakeSteps 1;
BA_ "SPN" SG_ 2563768353 SwitBackLlluminatBrightPercent 5532;
BA_ "SystemSignalLongSymbol" SG_ 2566722849 FlagSetWhenRegenerativeChargingA "FlagSetWhenRegenerativeChargingAllowable";
BA_ "SPN" SG_ 2566860833 SOH 520719;
BA_ "GenSigStartValue" SG_ 2566860833 SOH 255;
BA_ "SPN" SG_ 2566860833 SOHStatus 520720;
BA_ "GenSigStartValue" SG_ 2566860833 SOHStatus 3;
BA_ "SPN" SG_ 2566909985 BCM_NM_DA 520709;
BA_ "GenSigSendType" SG_ 2566909985 BCM_NM_DA 2;
BA_ "SPN" SG_ 2566909985 BCM_NM_Limphome 520712;
BA_ "GenSigSendType" SG_ 2566909985 BCM_NM_Limphome 2;
BA_ "SPN" SG_ 2566909985 BCM_NM_Sleep_Ind 520713;
BA_ "GenSigSendType" SG_ 2566909985 BCM_NM_Sleep_Ind 2;
BA_ "SPN" SG_ 2566909985 BCM_NM_Sleep_Ack 520714;
BA_ "GenSigSendType" SG_ 2566909985 BCM_NM_Sleep_Ack 2;
BA_ "SPN" SG_ 2566909985 BCM_NM_Alive 520710;
BA_ "GenSigSendType" SG_ 2566909985 BCM_NM_Alive 2;
BA_ "SPN" SG_ 2566909985 BCM_NM_Ring 520711;
BA_ "GenSigSendType" SG_ 2566909985 BCM_NM_Ring 2;
BA_ "SPN" SG_ 2564816929 ParticulatetrapregenerationInhib 3695;
BA_ "SystemSignalLongSymbol" SG_ 2564816929 ParticulatetrapregenerationInhib "ParticulatetrapregenerationInhibitswitch";
BA_ "SPN" SG_ 2564816929 ParticulatetrapregenerationForce 3696;
BA_ "SystemSignalLongSymbol" SG_ 2564816929 ParticulatetrapregenerationForce "ParticulatetrapregenerationForceswitch";
BA_ "SPN" SG_ 2431649768 LaneDepartureImminentRightSide 1701;
BA_ "SPN" SG_ 2431649768 LaneDepartureImminentLeftSide 1700;
BA_ "SPN" SG_ 2566806504 IHC_State 521728;
BA_ "SPN" SG_ 2566806504 IHC_Mainbeam_Request 521729;
BA_ "SPN" SG_ 2566806504 LaneTrackingStatusRightSide 1711;
BA_ "SPN" SG_ 2566806504 LDW_Sensitivity1 521737;
BA_ "SPN" SG_ 2566806504 TSR_State 521730;
BA_ "SPN" SG_ 2566806504 LaneTrackingStatusLeftSide 1710;
BA_ "SPN" SG_ 2566806504 TSR_Targetspeed_Request 521731;
BA_ "SPN" SG_ 2566806504 LDW_State 521732;
BA_ "SPN" SG_ 2566806504 Camer_State 521733;
BA_ "SPN" SG_ 2566806504 LaneDepartIndicationEnableSta 1702;
BA_ "SPN" SG_ 2432593706 SpeOfForVehicle 1586;
BA_ "SPN" SG_ 2432593706 AdaCruiseCrlSetSpeed 1588;
BA_ "SPN" SG_ 2432593706 AdapCruiseCtrlMode 1590;
BA_ "SPN" SG_ 2432593706 AdaptiveCruiseCtrlSetDistanceMod 1589;
BA_ "SystemSignalLongSymbol" SG_ 2432593706 AdaptiveCruiseCtrlSetDistanceMod "AdaptiveCruiseCtrlSetDistanceMode";
BA_ "SPN" SG_ 2432593706 RoadCurvature 1591;
BA_ "SPN" SG_ 2432593706 ACCTargetDetected 1798;
BA_ "SPN" SG_ 2432593706 ACCShutoffWarn 1797;
BA_ "SPN" SG_ 2432593706 ACCDistanceAlertSignal 1796;
BA_ "SPN" SG_ 2432593706 ForwardCollisionWarning 5022;
BA_ "SPN" SG_ 2432593706 DisToForVehicle 1587;
BA_ "SPN" SG_ 2364550954 AdvancedEmergencyBrakingSystemSt 5676;
BA_ "SystemSignalLongSymbol" SG_ 2364550954 AdvancedEmergencyBrakingSystemSt "AdvancedEmergencyBrakingSystemState";
BA_ "SPN" SG_ 2364550954 Bendoffprobabilityofrelevantobje 5679;
BA_ "SystemSignalLongSymbol" SG_ 2364550954 Bendoffprobabilityofrelevantobje "Bendoffprobabilityofrelevantobject";
BA_ "SPN" SG_ 2364550954 Timetocollisionwithrelevantobjec 5680;
BA_ "SystemSignalLongSymbol" SG_ 2364550954 Timetocollisionwithrelevantobjec "Timetocollisionwithrelevantobject";
BA_ "SPN" SG_ 2364550954 Collisionwarninglevel 5677;
BA_ "SPN" SG_ 2364550954 FCW_Sensitivity1 521736;
BA_ "SPN" SG_ 2364550954 Relevantobjectdetectedforadvance 5678;
BA_ "SystemSignalLongSymbol" SG_ 2364550954 Relevantobjectdetectedforadvance "Relevantobjectdetectedforadvancedemergencybrakingsystem";
BA_ "GenSigSendType" SG_ 2566906619 RemoteLockorUnlock 4;
BA_ "GenSigSendType" SG_ 2566906619 RemoteHornAlarm 4;
BA_ "GenSigSendType" SG_ 2566906619 RemoteLampFlash 4;
BA_ "GenSigSendType" SG_ 2566906875 VINStateResponse 4;
BA_ "GenSigSendType" SG_ 2566906875 LoanState 4;
BA_ "SPN" SG_ 2566842107 Seconds1 959;
BA_ "SPN" SG_ 2566842107 Hours1 961;
BA_ "SPN" SG_ 2566842107 Month1 962;
BA_ "SPN" SG_ 2566842107 Day1 963;
BA_ "SPN" SG_ 2566842107 Year1 964;
BA_ "SPN" SG_ 2566842107 LocalMinuteOffset1 1601;
BA_ "SPN" SG_ 2566842107 LocalHourOffset1 1602;
BA_ "SPN" SG_ 2566842107 Minutes1 960;
BA_ "SPN" SG_ 2566845491 Tire_Location1 3193;
BA_ "SPN" SG_ 2566845491 Tire_temperature 242;
BA_ "SPN" SG_ 2566845491 TireAirLeakageRate 2586;
BA_ "SPN" SG_ 2566845491 TirePressureThresholdDetection 2587;
BA_ "SPN" SG_ 2566845491 Tire_Pressure 241;
BA_ "SPN" SG_ 2566764851 Tire_Location2 3190;
BA_ "SPN" SG_ 2566764851 ReferenceTire_Pressure 3191;
BA_ "SPN" SG_ 2365479471 NominalLevelFrontAxle 1734;
BA_ "SPN" SG_ 2365479471 BelowNominalLevelRearAxle 1754;
BA_ "SPN" SG_ 2365479471 AboveNominalLevelFrontAxle 1737;
BA_ "SPN" SG_ 2365479471 AboveNominalLevelRearAxle 1736;
BA_ "SPN" SG_ 2365479471 LoweringControlModeFrontAxle 1740;
BA_ "SPN" SG_ 2365479471 LoweringControlModeRearAxle 1755;
BA_ "SPN" SG_ 2365479471 LiftingControlModeFrontAxle 1739;
BA_ "SPN" SG_ 2365479471 LiftingControlModeRearAxle 1756;
BA_ "SPN" SG_ 2365479471 LevelControlMode 1741;
BA_ "SPN" SG_ 2365479471 LiftAxle1Position 1743;
BA_ "SPN" SG_ 2365479471 NominallevelFrontAxle 1733;
BA_ "SPN" SG_ 2365479471 FrontAxleInBumperRange 1824;
BA_ "SPN" SG_ 2365479471 RearAxleInBumperRange 1823;
BA_ "SPN" SG_ 2365479471 SuspensionRemoteControl_1 1826;
BA_ "SPN" SG_ 2365479471 SuspensionControlRefusalInformat 1827;
BA_ "SystemSignalLongSymbol" SG_ 2365479471 SuspensionControlRefusalInformat "SuspensionControlRefusalInformation";
BA_ "SPN" SG_ 2365479471 BelowNominalLevelFrontAxle 1738;
BA_ "SPN" SG_ 2566805807 Relativelevelfrontaxleleft 1721;
BA_ "SPN" SG_ 2566805807 Relativelevelfrontaxleright 1722;
BA_ "SPN" SG_ 2566805807 Relativelevelrearaxleleft 1724;
BA_ "SPN" SG_ 2566805807 Relativelevelrearaxleright 1723;
BA_ "SPN" SG_ 2566805551 Bellowpressurefrontaxleleft 1725;
BA_ "SPN" SG_ 2566805551 Bellowpressurefrontaxleright 1726;
BA_ "SPN" SG_ 2566805551 Bellowpressurerearaxleleft 1727;
BA_ "SPN" SG_ 2566805551 Bellowpressurerearaxleright 1728;
BA_ "SystemSignalLongSymbol" SG_ 2566882563 WorkshopRequestedOrSpannerWarnin "WorkshopRequestedOrSpannerWarning";
BA_ "SPN" SG_ 2566882563 PTO1Active 5033;
BA_ "SPN" SG_ 2566882563 PTO2Active 5721;
BA_ "SPN" SG_ 2566801923 TransmissionEngineCrankEnable 2900;
BA_ "SPN" SG_ 2566801923 TransmissionMode4indicator 2539;
BA_ "SPN" SG_ 2566801923 TransmissionMode3indicator 2538;
BA_ "SPN" SG_ 2566801923 TransmissionMode2indicator 2537;
BA_ "SPN" SG_ 2566801923 TransmissionMode1indicator 2536;
BA_ "SPN" SG_ 2566834735 AmberWarningLampStatus 624;
BA_ "GenSigSendType" SG_ 2566901812 PEPS_RkeCmd 1;
BA_ "GenSigSendType" SG_ 2566901812 PEPS_TrunkSwPress_Resvered 4;
BA_ "GenSigSendType" SG_ 2566901812 PEPS_BCMAlarm 4;
BA_ "GenSigSendType" SG_ 2566901812 PEPS_ICAlarm 4;
BA_ "GenSigSendType" SG_ 2566901812 PEPS_ICInd 4;
BA_ "GenSigSendType" SG_ 2566901812 PEPS_PkeCmd_Resvered 4;
BA_ "GenSigSendType" SG_ 2566901812 PEPS_FRSwPress_Resvered 4;
BA_ "GenSigSendType" SG_ 2566901812 PEPS_FLSwPress_Resvered 4;
BA_ "GenSigSendType" SG_ 2566902068 PEPS_EncryptedRsvd 1;
BA_ "GenSigSendType" SG_ 2566902068 PEPS_EncryptedResponseByte0 1;
BA_ "GenSigSendType" SG_ 2566902068 PEPS_EncryptedResponseByte1 1;
BA_ "GenSigSendType" SG_ 2566902068 PEPS_EncryptedResponseByte2 1;
BA_ "GenSigSendType" SG_ 2566902068 PEPS_EncryptedResponseByte3 1;
BA_ "GenSigSendType" SG_ 2566902068 PEPS_EncryptedResponseByte4 1;
BA_ "GenSigSendType" SG_ 2566902068 PEPS_EncryptedResponseByte5 1;
BA_ "GenSigSendType" SG_ 2566902068 PEPS_EncryptedStatus 1;
BA_ "GenSigSendType" SG_ 2566910004 PEPS_NM_DA 2;
BA_ "GenSigSendType" SG_ 2566910004 PEPS_NM_Limphome 2;
BA_ "GenSigSendType" SG_ 2566910004 PEPS_NM_Sleep_Ind 2;
BA_ "GenSigSendType" SG_ 2566910004 PEPS_NM_Sleep_Ack 2;
BA_ "GenSigSendType" SG_ 2566910004 PEPS_NM_Alive 2;
BA_ "GenSigSendType" SG_ 2566910004 PEPS_NM_Ring 2;
BA_ "SPN" SG_ 2566783796 ESCLCommand 516418;
BA_ "SPN" SG_ 2566783796 PowerMode 516420;
BA_ "SPN" SG_ 2566783796 PSAliveCounter 516421;
BA_ "SPN" SG_ 2566783796 PS_CRC 516422;
BA_ "SPN" SG_ 2564640052 Anti_theftEncryptionIndicatorSta 1199;
BA_ "GenSigSendType" SG_ 2564640052 Anti_theftEncryptionIndicatorSta 4;
BA_ "SystemSignalLongSymbol" SG_ 2564640052 Anti_theftEncryptionIndicatorSta "Anti_theftEncryptionIndicatorStates";
BA_ "SPN" SG_ 2564640052 Anti_theftDesiredExitModeStates 1200;
BA_ "GenSigSendType" SG_ 2564640052 Anti_theftDesiredExitModeStates 4;
BA_ "SPN" SG_ 2564640052 Anti_theftCommandStates 1201;
BA_ "GenSigSendType" SG_ 2564640052 Anti_theftCommandStates 4;
BA_ "SPN" SG_ 2564640052 Anti_theftPasswordRepresentation 1202;
BA_ "GenSigSendType" SG_ 2564640052 Anti_theftPasswordRepresentation 4;
BA_ "SPN" SG_ 2565865488 RetarderTorqueMode1 900;
BA_ "SPN" SG_ 2565865488 EngineCoolantLoadIncrease1 1082;
BA_ "SPN" SG_ 2565865488 RetarderRequestingBrakeLight1 1667;
BA_ "SPN" SG_ 2565865488 SourceAddressControllingDeviceFo 1480;
BA_ "SystemSignalLongSymbol" SG_ 2565865488 SourceAddressControllingDeviceFo "SourceAddressControllingDeviceForRetarderControl";
BA_ "SPN" SG_ 2565865488 DriversDemandRetarderPercentTorq 1715;
BA_ "SystemSignalLongSymbol" SG_ 2565865488 DriversDemandRetarderPercentTorq "DriversDemandRetarderPercentTorque";
BA_ "SPN" SG_ 2565865488 RetarderSelectionNon_engine 1716;
BA_ "SPN" SG_ 2565865488 ActualMaximumAvailableRetarderPe 1717;
BA_ "SystemSignalLongSymbol" SG_ 2565865488 ActualMaximumAvailableRetarderPe "ActualMaximumAvailableRetarderPercentTorque";
BA_ "SPN" SG_ 2565865488 ActualRetarderPercentTorque1 520;
BA_ "SPN" SG_ 2566905966 SYSDisplayRequest 522112;
BA_ "SPN" SG_ 2566905966 TargetDetection 522113;
BA_ "SPN" SG_ 2566905966 TargetDistanceLevel 522115;
BA_ "SPN" SG_ 2566905966 TargetDetectionAlarm 522116;
BA_ "SPN" SG_ 2566905966 TargetDistance 522114;
BA_ "SPN" SG_ 2564568141 Anti_theftEncryptionSeedPresentI 1194;
BA_ "GenSigSendType" SG_ 2564568141 Anti_theftEncryptionSeedPresentI 4;
BA_ "SystemSignalLongSymbol" SG_ 2564568141 Anti_theftEncryptionSeedPresentI "Anti_theftEncryptionSeedPresentIndicator";
BA_ "SPN" SG_ 2564568141 Anti_theftPasswordValidIndicator 1195;
BA_ "GenSigSendType" SG_ 2564568141 Anti_theftPasswordValidIndicator 4;
BA_ "SPN" SG_ 2564568141 Anti_theftComponentStatusStates 1196;
BA_ "GenSigSendType" SG_ 2564568141 Anti_theftComponentStatusStates 4;
BA_ "SPN" SG_ 2564568141 Anti_theftModifyPasswordStates 1197;
BA_ "GenSigSendType" SG_ 2564568141 Anti_theftModifyPasswordStates 4;
BA_ "SPN" SG_ 2564568141 Anti_theftRandomNumber 1198;
BA_ "GenSigSendType" SG_ 2564568141 Anti_theftRandomNumber 4;
BA_ "SPN" SG_ 2566784333 ESCLUnlockSensor2Sts 516416;
BA_ "SPN" SG_ 2566784333 UnlockingRunning 516423;
BA_ "SPN" SG_ 2566784333 ESCLAliveCounter 516424;
BA_ "SPN" SG_ 2566784333 ESCLUnlockSensor1Sts 516417;
BA_ "SPN" SG_ 2566784333 ESCL_CRC 516425;
BA_ "SPN" SG_ 2566784333 ESCLUnlockSensorsSts 516418;
BA_ "SPN" SG_ 2566784333 ESCLLockSensorSts 516421;
BA_ "SPN" SG_ 2566784333 LockingRunning 516422;
BA_ "SPN" SG_ 2565866755 SelectedGear 524;
BA_ "SPN" SG_ 2565866755 CurrentGear 523;
BA_ "SPN" SG_ 2565866755 ActualGearRatio 526;
BA_ "SPN" SG_ 2566845555 Tire_Location_TESD 3193;
BA_ "SPN" SG_ 2566845555 Tire_temperature_TESD 242;
BA_ "SPN" SG_ 2566845555 CTIWheelEndElectricalFault 2586;
BA_ "SPN" SG_ 2566845555 CTITireStatus 1697;
BA_ "SPN" SG_ 2566845555 Tire_Pressure_TESD 241;
VAL_ 2566838561 Passenger_Door_Status 3 "Not available" 2 "error" 1 "open" 0 "closed" ;
VAL_ 2566838561 Current_Power_Supply_Status 3 "START（not support）" 2 "ON" 1 "ACC" 0 "OFF（not support）" ;
VAL_ 2566838561 Driver_Door_Status 3 "Not available" 2 "error" 1 "open" 0 "closed" ;
VAL_ 2566838561 Door_Locked_Status 3 "Not available" 2 "error" 1 "locked" 0 "Not Locked" ;
VAL_ 2565867041 RearAxle1 3 "Not available" 2 "error" 1 "Differential Lock engaged" 0 "Differential Lock Disengaged 差速锁" ;
VAL_ 2565867041 RearAxle2 3 "Not available" 2 "error" 1 "Differential Lock engaged" 0 "Differential Lock Disengaged" ;
VAL_ 2565867041 Interlock 3 "Not available" 2 "error" 1 "Differential Lock engaged" 0 "Differential Lock Disengaged" ;
VAL_ 2566844705 CruiseControlEnableSwitch 3 "Not available" 2 "error" 1 "Cruise Control abled" 0 "Cruise Control disabled" ;
VAL_ 2566844705 ASLDEnableSwitch 3 "Not available" 2 "error" 1 "Actuated" 0 "Not actuated" ;
VAL_ 2566844705 CruiseOFFswitch 3 "Not available" 2 "error" 1 "Actuated" 0 "Not actuated" ;
VAL_ 2566844705 CruiseDeaccelerateSwitch 3 "Not available" 2 "error" 1 "Actuated" 0 "Not actuated" ;
VAL_ 2566844705 CruiseResumeSwitch 3 "Not available" 2 "error" 1 "Actuated" 0 "Not actuated" ;
VAL_ 2566844705 CruiseAccelerateSwitch 3 "Not available" 2 "error" 1 "Actuated" 0 "Not actuated" ;
VAL_ 2566844705 CruiseControlpauseOrcancelSwitch 3 "Not available" 2 "error" 1 "Actuated" 0 "Not actuated" ;
VAL_ 2566844705 PTOstate 1 "HOLD" 0 "Off / Disabled" ;
VAL_ 2566844705 PTOApplicationMode 7 "sig error" 6 "min error" 5 "max error" 4 "not plausible" 3 "mode 3" 2 "mode 2" 1 "mode 1" 0 "mode 0" ;
VAL_ 2566799393 VehicleHorn 3 "NotAvailable" 2 "Error" 1 "Activated" 0 "Deactivated" ;
VAL_ 2566799393 TractorRightTurnLightSts 3 "NotAvailable" 2 "Error" 1 "Activated" 0 "Deactivated" ;
VAL_ 2566799393 TractorLeftTurnLightSts 3 "NotAvailable" 2 "Error" 1 "Activated" 0 "Deactivated" ;
VAL_ 2566799393 TractorMarkerLighStst 3 "NotAvailable" 2 "Error" 1 "Activated" 0 "Deactivated" ;
VAL_ 2566799393 RearFogLights 3 "NotAvailable" 2 "Error" 1 "Activated" 0 "Deactivated" ;
VAL_ 2566799393 TrailerLeftTurnLightSts 3 "NotAvailable" 2 "Error" 1 "Activated" 0 "Deactivated" ;
VAL_ 2566799393 TrailerRightTurnLightSts 3 "NotAvailable" 2 "Error" 1 "Activated" 0 "Deactivated" ;
VAL_ 2566799393 TractorMarkerLighOpenWaring 3 "NotAvailable" 2 "Error" 1 "open waring" 0 "no open waring" ;
VAL_ 2566799393 FrontFogLights 3 "NotAvailable" 2 "Error" 1 "Activated" 0 "Deactivated" ;
VAL_ 2365443105 HazardLightSwitchSignal 3 "NotAvailable" 2 "error" 1 "Hazard Lamps to be flashing" 0 "Hazard lamps to be off" ;
VAL_ 2365443105 MainSwitch 15 "not available" 14 "error" 13 "reserved" 12 "reserved" 11 "reserved" 10 "reserved" 9 "reserved" 8 "delayed off" 7 "reserved" 6 "reserved" 5 "reserved" 4 "auto 档" 3 "headlight and park on" 2 "headlight on" 1 "PARK ON" 0 "OFF" ;
VAL_ 2365443105 WiperMotorGear 15 "NotAvailable" 14 "error" 13 "Reserved" 12 "Reserved" 11 "Reserved" 10 "Reserved" 9 "Reserved" 8 "reserved" 7 "高速档" 6 "低速档" 5 "间歇Level 5/自动档5档" 4 "间歇Level 4/自动档4档" 3 "间歇Level 3/自动档3档" 2 "间歇Level 2/自动档2档" 1 "间歇Level 1/自动档1档" 0 "Off" ;
VAL_ 2365443105 HighBeamSwitchStatus 3 "NotAvailable" 2 "error" 1 "on" 0 "off" ;
VAL_ 2365443105 OvertakingSwitchStatus 3 "NotAvailable" 2 "error" 1 "on" 0 "off" ;
VAL_ 2365443105 HighLowBeamStatus 3 "NotAvailable" 2 "error" 1 "High Beam Selected" 0 "Low Beam Selected" ;
VAL_ 2365443105 WiperActive 3 "NotAvailable" 2 "error" 1 "Wiper active" 0 "Wiper is not active" ;
VAL_ 2365443105 LowBeamStatus 3 "NotAvailable" 2 "error" 1 "Low Beam  Active" 0 "Low Beam Not Active" ;
VAL_ 2365443105 TurnSignalSwitch 15 "NotAvailable" 14 "error" 2 "Right turn to be Flashing" 1 "Left Turn to be Flashing" 0 "No Turn being signaled" ;
VAL_ 2348875809 ReverseGear 255 "NotAvailable" 254 "error" 240 "Not defined" 223 "Gear in reverse position" 1 "Not defined" 0 "Not in reverse gear" ;
VAL_ 2348875809 RearviewMirrorHeating 3 "Not available" 2 "error" 1 "heat" 0 "not heat" ;
VAL_ 2566870305 BremsomatSwitch 3 "Not available" 2 "Reserved" 1 "Bremsomat Switch in position on" 0 "Bremsomat Switch in position off" ;
VAL_ 2566870305 Hand_Lever_Signals 31 "Position 5(intaeder 4制动四档)" 15 "Position 4(intaeder 3制动三档)" 7 "Position 3(intaeder 2制动二档)" 3 "Position 2(intaeder 1制动一档)" 1 "Position 1(bremsomat/Constant speed gear恒速档)" 0 "off" ;
VAL_ 2566722849 FlagSetWhenBMSHealthy 3 "NotAvailable" 2 "Error" 1 "Flag Set" 0 "Flag not set" ;
VAL_ 2566722849 FlagSetWhenRegenerativeChargingA 3 "NotAvailable" 2 "Error" 1 "Flag Set" 0 "Flag not set" ;
VAL_ 2566722849 FlagSetWhenDischargingAllowable 3 "NotAvailable" 2 "Error" 1 "Flag Set" 0 "Flag not set" ;
VAL_ 2566722849 ChargeMode 15 "Error" 14 "Mode 14" 13 "Mode 13" 12 "Mode 12" 11 "Mode 11" 10 "Mode 10" 9 "Mode 9" 8 "Mode 8" 7 "Mode 7" 6 "Mode 6" 5 "Mode 5" 4 "Mode 4" 3 "Mode 3" 2 "Mode 2" 1 "Mode 1" 0 "Mode 0" ;
VAL_ 2566722593 BatteryLow 3 "reserve" 2 "reserve" 1 "low（电量低）" 0 "normal（正常）" ;
VAL_ 2566860833 SOHStatus 3 "reserved" 2 "error" 1 "not health" 0 "health" ;
VAL_ 2566909985 BCM_NM_DA 251 "TBOX" 76 "MP5" 52 "PEPS" 33 "BCM" 25 "EATC" 23 "ICM" ;
VAL_ 2566909985 BCM_NM_Limphome 1 "Ture" 0 "False" ;
VAL_ 2566909985 BCM_NM_Sleep_Ind 1 "Ture" 0 "False" ;
VAL_ 2566909985 BCM_NM_Sleep_Ack 1 "Ture" 0 "False" ;
VAL_ 2566909985 BCM_NM_Alive 1 "Ture" 0 "False" ;
VAL_ 2566909985 BCM_NM_Ring 1 "Ture" 0 "False" ;
VAL_ 2564816929 ParticulatetrapregenerationInhib 3 "NotAvailable" 2 "Error" 1 "active" 0 "Not active" ;
VAL_ 2564816929 ParticulatetrapregenerationForce 3 "NotAvailable" 2 "Error" 1 "active" 0 "Not active" ;
VAL_ 2566803745 BCM_ACCusagedemand 3 "reserved" 2 "reserved" 1 "the driver demand for  using ACC distance keeping control" 0 "the driver demand for not using ACC distance keeping control" ;
VAL_ 2566803745 BCM_RequestedACCDistanceMode 7 "not available" 6 "error condition" 5 "not defined" 4 "requested ACC distance mode #5(shortest distance)" 3 "requested ACC distance mode #4" 2 "requested ACC distance mode #3" 1 "requested ACC distance mode #2" 0 "requested ACC distance mode #1(largest distance)" ;
VAL_ 2349541921 BCM_AEBS2_EnableSwitch 3 "don’t care / take no action" 2 "Error" 1 "no deactivation of AEBS" 0 "deactivation of AEBS" ;
VAL_ 2349541921 BCM_AEBS2MessageCounter 4 "Not available" 3 "Error" 1 "Trailer ABS detected" 0 "Trailer ABS not detected" ;
VAL_ 2349541921 BCM_AEBS2MessageChecksum 4 "Not available" 3 "Error" 1 "Trailer detected" 0 "Trailer not detected" ;
VAL_ 2431649768 LaneDepartureImminentRightSide 3 "NotAvailable" 2 "Error" 1 "imminent（车道偏离报警，右侧）" 0 "Not imminent（无报警）" ;
VAL_ 2431649768 OpticalWarningRightSide 3 "Not Available" 2 "Error indicator" 1 "active" 0 "inactive" ;
VAL_ 2431649768 OpticalWarningLeftSide 3 "Not Available" 2 "Error indicator" 1 "active" 0 "inactive" ;
VAL_ 2431649768 LaneDepartureImminentLeftSide 3 "NotAvailable" 2 "Error" 1 "imminent（车道偏离报警，左侧）" 0 "Not imminent（无报警）" ;
VAL_ 2431649768 AcousticalWarningRightSide 3 "Not Available" 2 "Error indicator" 1 "active" 0 "inactive" ;
VAL_ 2431649768 AcousticalWarningLeftSide 3 "Not Available" 2 "Error indicator" 1 "active" 0 "inactive" ;
VAL_ 2566806504 IHC_State 15 "Reserved" 14 "Error(故障状态，摄像头故障或者被遮挡)" 4 "Active（功能开启，有报警）" 3 "Active (no intervention)（功能开启，无报警）" 2 "Standby（功能开启，未满足车速工作条件）" 1 "Off（关闭状态）" 0 "Unavailable state（车型未配置该功能）" ;
VAL_ 2566806504 IHC_Mainbeam_Request 3 "Reserved" 2 "High Beam OFF（远光灯关闭）" 1 "High Beam ON（远光灯开启）" 0 "Default State（当前状态）" ;
VAL_ 2566806504 LaneTrackingStatusRightSide 3 "Don’t care/take no action" 2 "Reserved" 1 "tracking right side（右侧车道线已被识别）" 0 "Not tracking right side（右侧车道线未识别）" ;
VAL_ 2566806504 LDWSSwitch 3 "Reserved" 2 "error" 1 "enable" 0 "disable" ;
VAL_ 2566806504 LDW_Sensitivity1 15 "Reserved" 14 "Error（故障状态）" 3 "Level 3 (LDW等级，高)" 2 "Level 2" 1 "Level 1 (LDW等级，低)" 0 "Reserved" ;
VAL_ 2566806504 TSR_State 15 "Reserved" 14 "Error(故障状态，摄像头故障或者被遮挡)" 5 "Active no waring ,Unidentified sign（功能开启，无报警，未识别到标识牌）" 4 "Active（功能开启，有报警，已超速）" 3 "Active (no intervention)（功能开启，无报警，未超速）" 2 "Standby（功能开启，未满足车速工作条件）" 1 "Off（关闭状态）" 0 "Unavailable state（车型未配置该功能）" ;
VAL_ 2566806504 LaneTrackingStatusLeftSide 3 "Don’t care/take no action" 2 "Reserved" 1 "tracking left side（左侧车道线已被识别）" 0 "Not tracking left side（左侧车道线未识别）" ;
VAL_ 2566806504 TSR_Targetspeed_Request 254 "Error(故障状态，摄像头故障或者被遮挡)" 253 ",Unidentified sign未识别到标识牌" ;
VAL_ 2566806504 LDW_State 15 "not available" 14 "Error indication" 5 "system is warning（系统OK，有报警）" 4 "driver overrides system（待定）" 3 "system is ready(no waring active)（系统OK，无报警）" 2 "system is deactivated by driver（系统被驾驶员关闭）" 1 "system is temporarily not available(not all activation conditions fulfilloed)（系统暂时不可用，有条件未满足，类似StandBy状态）" 0 "system is not ready(initialization not finished)（系统初始化未完成）" ;
VAL_ 2566806504 Camer_State 15 "not available" 14 "Error (摄像头故障)" 6 "calibrating(标定中)" 5 "Uncalibrated（未标定）" 4 "environmental unavailable（外部环境条件不可支持）" 3 "blocked（完全遮挡）" 2 "partially blocked（部分遮挡）" 1 "warming up（正在初始化）" 0 "fully Operational（状态OK）" ;
VAL_ 2566806504 LaneDepartIndicationEnableSta 3 "Reserved" 2 "Reserved" 1 "Lane departure indication enabled（车道偏离指示启用）" 0 "Lane departure indication disabled（车道偏离指示失效）" ;
VAL_ 2432593706 AdapCruiseCtrlMode 7 "Not available/not valid" 6 "Disabled or error condition" 5 "Finish mode" 4 "Hold mode" 3 "Overtake mode" 2 "Distance control active" 1 "Speed control active" 0 "Off (Standby, enabled, ready for activation)" ;
VAL_ 2432593706 AdaptiveCruiseCtrlSetDistanceMod 7 "Not available/not valid" 6 "Error condition" 5 "Conventional cruise control mode" 4 "ACC Distance mode #5 (shortest distance)" 3 "ACC Distance mode #4" 2 "ACC Distance mode #3" 1 "ACC Distance mode #2" 0 "ACC Distance mode #1 (largest distance)" ;
VAL_ 2432593706 ACCTargetDetected 3 "Take no action" 2 "Reserved" 1 "Target detected" 0 "No targets detected" ;
VAL_ 2432593706 ACCShutoffWarn 3 "Take no action" 2 "Reserved" 1 "ACC SSOW Active" 0 "ACC SSOW Not Active" ;
VAL_ 2432593706 ACCDistanceAlertSignal 3 "Take no action" 2 "Reserved" 1 "ACC DAS Active" 0 "ACC DAS Not Active" ;
VAL_ 2432593706 ForwardCollisionWarning 3 "not available" 2 "Error indicator" 1 "Collision is imminent" 0 "No warning" ;
VAL_ 2364550954 AdvancedEmergencyBrakingSystemSt 15 "not available / not installed" 14 "error indication" 13 "reserved for future use" 12 "reserved for future use" 11 "reserved for future use" 10 "reserved for future use" 9 "reserved for future use" 8 "system performance and/or sensitivity limited (no warning and no braking active)" 7 "emergency braking active" 6 "collision warning with braking (e.g. brake jerk or partial braking)" 5 "collision warning active (e.g. acoustic signal, cruise control turned off, torque limitation)" 4 "driver overrides system" 3 "system is ready and activated (no warning and no braking active)" 2 "system is deactivated by driver" 1 "system is temporarily not available (e.g. due to boundary conditions necessary for operation)" 0 "system is not ready (initialization not finished)" ;
VAL_ 2364550954 Bendoffprobabilityofrelevantobje 7 "signal not available / not installed" 6 "error indication" 5 "relevant object is already in a turning maneuver" 4 "highest probability for a bend off maneuver of the relevant object" 3 "high probability for a bend off maneuver of the relevant object" 2 "medium probability for a bend off maneuver of the relevant object" 1 "low probability for a bend off maneuver of the relevant object" 0 "no indication for a bend off maneuver of the relevant object" ;
VAL_ 2364550954 Collisionwarninglevel 15 "don’t care / take no action" 14 "reserved" 13 "reserved" 12 "reserved" 11 "reserved" 10 "reserved" 9 "reserved" 8 "reserved" 7 "warning level 7 - highest" 6 "warning level 6" 5 "warning level 5" 4 "warning level 4" 3 "warning level 3" 2 "warning level 2" 1 "warning level 1 - lowest" 0 "no warning" ;
VAL_ 2364550954 FCW_Sensitivity1 15 "Reserved" 14 "Error（故障状态）" 3 "Level 3 (FCW等级，高)" 2 "Level 2" 1 "Level 1 (FCW等级，低)" 0 "Reserved" ;
VAL_ 2364550954 Relevantobjectdetectedforadvance 7 "signal not available / not installed" 6 "error indication" 5 "reserved" 4 "reserved" 3 "reserved" 2 "relevant object is not being detected reliably" 1 "relevant object is being monitored" 0 "no relevant object monitored" ;
VAL_ 2566906619 RemoteLockorUnlock 3 "Reserved" 2 "Unlock activate" 1 "Lock activate" 0 "Current Status" ;
VAL_ 2566906619 RemoteHornAlarm 3 "Reserved" 2 "Alarm activate" 1 "Alarm deactivate" 0 "Current Status" ;
VAL_ 2566906619 RemoteLampFlash 3 "Reserved" 2 "Flash activate" 1 "Flash deactivate" 0 "Current Status" ;
VAL_ 2566906875 VINStateResponse 3 "Reserved" 2 "Reserved" 1 "VIN Inconsistent" 0 "VIN Consistent" ;
VAL_ 2566906875 LoanState 15 "Reserved" 14 "Reserved" 13 "Reserved" 12 "Reserved" 11 "Reserved" 10 "Reserved" 9 "Reserved" 8 "Reserved" 7 "Reserved" 6 "Reserved" 5 "Reserved" 4 "Reserved" 3 "Reserved" 2 "Reserved" 1 "Arrears" 0 "No Arrears" ;
VAL_ 2566845491 SensorStatus 3 "Not Study Sensor ID" 2 "Sensor Failure" 1 "Battery Low" 0 "Sensor OK" ;
VAL_ 2566845491 TireAirLeakageStatus 3 "Reserved" 2 "Error" 1 "Rapid Air Leakage" 0 "Tire Air Leakage OK" ;
VAL_ 2566845491 VehicleLocation 7 "Reserved" 6 "Reserved" 5 "Dolly" 4 "Reserved" 3 "Tractor3" 2 "Tractor2" 1 "Tractor1" 0 "Tractor" ;
VAL_ 2566845491 TireTempThresholdDetection 3 "Reserved" 2 "Reserved" 1 "Over  temperature" 0 "No warning temperature (OK)" ;
VAL_ 2566845491 TirePressureThresholdDetection 7 "Reserved" 6 "Error" 5 "Not Defined" 4 "Extreme under pressure" 3 "Under pressure" 2 "No warning pressure" 1 "Over pressure" 0 "Extreme over pressure" ;
VAL_ 2566764851 ReferenceTireSettingASK 255 "Reserved" 254 "Reserved" 253 "Reserved" 252 "Reserved" 251 "Reserved" 250 "Reserved" 249 "Reserved" 248 "Reserved" 247 "Reserved" 246 "Reserved" 245 "Reserved" 244 "Reserved" 243 "Reserved" 242 "Reserved" 241 "Reserved" 240 "Reserved" 239 "Reserved" 238 "Reserved" 237 "Reserved" 236 "Reserved" 235 "Reserved" 234 "Reserved" 233 "Reserved" 232 "Reserved" 231 "Reserved" 230 "Reserved" 229 "Reserved" 228 "Reserved" 227 "Reserved" 226 "Reserved" 225 "Reserved" 224 "Reserved" 223 "Reserved" 222 "Reserved" 221 "Reserved" 220 "Reserved" 219 "Reserved" 218 "Reserved" 217 "Reserved" 216 "Reserved" 215 "Reserved" 214 "Reserved" 213 "Reserved" 212 "Reserved" 211 "Reserved" 210 "Reserved" 209 "Reserved" 208 "Reserved" 207 "Reserved" 206 "Reserved" 205 "Reserved" 204 "Reserved" 203 "Reserved" 202 "Reserved" 201 "Reserved" 200 "Reserved" 199 "Reserved" 198 "Reserved" 197 "Reserved" 196 "Reserved" 195 "Reserved" 194 "Reserved" 193 "Reserved" 192 "Reserved" 191 "Reserved" 190 "Reserved" 189 "Reserved" 188 "Reserved" 187 "Reserved" 186 "Reserved" 185 "Reserved" 184 "Reserved" 183 "Reserved" 182 "Reserved" 181 "Reserved" 180 "Reserved" 179 "Reserved" 178 "Reserved" 177 "Reserved" 176 "Reserved" 175 "Reserved" 174 "Reserved" 173 "Reserved" 172 "Reserved" 171 "Reserved" 170 "Reserved" 169 "Reserved" 168 "Reserved" 167 "Reserved" 166 "Reserved" 165 "Reserved" 164 "Reserved" 163 "Reserved" 162 "Reserved" 161 "Reserved" 160 "Reserved" 159 "Reserved" 158 "Reserved" 157 "Reserved" 156 "Reserved" 155 "Reserved" 154 "Reserved" 153 "Reserved" 152 "Reserved" 151 "Reserved" 150 "Reserved" 149 "Reserved" 148 "Reserved" 147 "Reserved" 146 "Reserved" 145 "Reserved" 144 "Reserved" 143 "Reserved" 142 "Reserved" 141 "Reserved" 140 "Reserved" 139 "Reserved" 138 "Reserved" 137 "Reserved" 136 "Reserved" 135 "Reserved" 134 "Reserved" 133 "Reserved" 132 "Reserved" 131 "Reserved" 130 "Reserved" 129 "Reserved" 128 "Reserved" 127 "Reserved" 126 "Reserved" 125 "Reserved" 124 "Reserved" 123 "Reserved" 122 "Reserved" 121 "Reserved" 120 "Reserved" 119 "Reserved" 118 "Reserved" 117 "Reserved" 116 "Reserved" 115 "Reserved" 114 "Reserved" 113 "Reserved" 112 "Reserved" 111 "Reserved" 110 "Reserved" 109 "Reserved" 108 "Reserved" 107 "Reserved" 106 "Reserved" 105 "Reserved" 104 "Reserved" 103 "Reserved" 102 "Reserved" 101 "Reserved" 100 "Reserved" 99 "Reserved" 98 "Reserved" 97 "Reserved" 96 "Reserved" 95 "Reserved" 94 "Reserved" 93 "Reserved" 92 "Reserved" 91 "Reserved" 90 "Reserved" 89 "Reserved" 88 "Reserved" 87 "Reserved" 86 "Reserved" 85 "Reserved" 84 "Reserved" 83 "Reserved" 82 "Reserved" 81 "Reserved" 80 "Reserved" 79 "Reserved" 78 "Reserved" 77 "Reserved" 76 "Reserved" 75 "Reserved" 74 "Reserved" 73 "Reserved" 72 "Reserved" 71 "Reserved" 70 "Reserved" 69 "Reserved" 68 "Reserved" 67 "Reserved" 66 "Reserved" 65 "Reserved" 64 "Reserved" 63 "Reserved" 62 "Reserved" 61 "Reserved" 60 "Reserved" 59 "Reserved" 58 "Reserved" 57 "Reserved" 56 "Reserved" 55 "Reserved" 54 "Reserved" 53 "Reserved" 52 "Reserved" 51 "Reserved" 50 "Reserved" 49 "Reserved" 48 "Reserved" 47 "Reserved" 46 "Reserved" 45 "Reserved" 44 "Reserved" 43 "Reserved" 42 "Reserved" 41 "Reserved" 40 "Reserved" 39 "Reserved" 38 "Reserved" 37 "Reserved" 36 "Reserved" 35 "Reserved" 34 "Reserved" 33 "Reserved" 32 "Reserved" 31 "Reserved" 30 "Reserved" 29 "Reserved" 28 "Reserved" 27 "Reserved" 26 "Reserved" 25 "Reserved" 24 "Reserved" 23 "Reserved" 22 "Reserved" 21 "Reserved" 20 "Reserved" 19 "Reserved" 18 "Reserved" 17 "Reserved" 16 "Reserved" 15 "Reserved" 14 "Reserved" 13 "Reserved" 12 "Reserved" 11 "Reserved" 10 "Reserved" 9 "Reserved" 8 "Reserved" 7 "ID Learn NOK" 6 "ID Learn OK" 5 "Learning Mode Activated" 4 "Reserved" 3 "Reserved" 2 "Reserved" 1 "Reserved" 0 "Reserved" ;
VAL_ 2365479471 NominalLevelFrontAxle 13 "Not defined" 12 "Not defined" 11 "Not defined" 10 "Not defined" 9 "Not defined" 8 "Not defined" 7 "Lower Level" 6 "Upper Level" 5 "Customer Level" 4 "Preset Level" 3 "Normal Level 3" 2 "Normal Level 2" 1 "Normal Level 1" 0 "Level not specified" ;
VAL_ 2365479471 BelowNominalLevelRearAxle 3 "Not available" 2 "Error" 1 "Below" 0 "Not below" ;
VAL_ 2365479471 AboveNominalLevelFrontAxle 3 "Not available" 2 "Error" 1 "Above" 0 "Not above" ;
VAL_ 2365479471 AboveNominalLevelRearAxle 3 "Not available" 2 "Error" 1 "Above" 0 "Not above" ;
VAL_ 2365479471 LoweringControlModeFrontAxle 3 "Not available" 2 "Error" 1 "Lowering active" 0 "Lowering not active" ;
VAL_ 2365479471 LoweringControlModeRearAxle 3 "Not available" 2 "Error" 1 "Lowering active" 0 "Lowering not active" ;
VAL_ 2365479471 LiftingControlModeFrontAxle 3 "Not available" 2 "Error" 1 "Lifting active" 0 "Lifting not active" ;
VAL_ 2365479471 LiftingControlModeRearAxle 3 "Not available" 2 "Error" 1 "Lifting active" 0 "Lifting not active" ;
VAL_ 2365479471 LevelControlMode 7 "Traction help (Load reduce)" 6 "Optimum Traction 2" 5 "Optimum Traction 1" 4 "Pressure ratio 2" 3 "Pressure ratio 1" 2 "Load fixing" 1 "Traction help (load transfer)" 0 "Normal operation" ;
VAL_ 2365479471 LiftAxle1Position 1 "lift axle position up / tag axle unladen" 0 "lift axle position down / tag axle laden" ;
VAL_ 2365479471 NominallevelFrontAxle 13 "Not defined" 12 "Not defined" 11 "Not defined" 10 "Not defined" 9 "Not defined" 8 "Not defined" 7 "Lower Level" 6 "Upper Level" 5 "Customer Level" 4 "Preset Level" 3 "Normal Level 3" 2 "Normal Level 2" 1 "Normal Level 1" 0 "除了NormalLevel,其他状态仪表都要点亮高度警报灯" 0 "Level not specified" ;
VAL_ 2365479471 FrontAxleInBumperRange 1 "Actual level within bumper range" 0 "Actual level out of bumper range" ;
VAL_ 2365479471 RearAxleInBumperRange 1 "Actual level within bumper range" 0 "Actual level out of bumper range" ;
VAL_ 2365479471 SuspensionRemoteControl_1 1 "Active" 0 "Not active" ;
VAL_ 2365479471 SuspensionControlRefusalInformat 13 "Not defined" 12 "Not defined" 11 "Not defined" 10 "Not defined" 9 "Not defined" 8 "Not defined" 7 "Not defined" 6 "General reject" 5 "Below speed limit" 4 "Above speed limit" 3 "Bogie differential not locked" 2 "Would exceed load limit (tag axle)" 1 "Axle load limit reached (load transfer)" 0 "Actual request not refused" ;
VAL_ 2365479471 BelowNominalLevelFrontAxle 3 ":Not available" 2 ":Error" 1 ":Below" 0 "Not below" ;
VAL_ 2566882563 STOPrequested 3 "Not available" 2 "error" 1 "active" 0 "not active" ;
VAL_ 2566882563 ClutchOverload 3 "Not available" 2 "error" 1 "active" 0 "not active" ;
VAL_ 2566882563 LowAirPressure 3 "Not available" 2 "error" 1 "active" 0 "not active" ;
VAL_ 2566882563 TemperatureTooHigh 3 "Not available" 2 "error" 1 "active" 0 "not active" ;
VAL_ 2566882563 CheckPhase 3 "Not available" 2 "error" 1 "active" 0 "not active" ;
VAL_ 2566882563 ReleaseAcceleratorPedal 3 "Not available" 2 "error" 1 "active" 0 "not active" ;
VAL_ 2566882563 WorkshopRequestedOrSpannerWarnin 3 "Not available" 2 "error" 1 "active" 0 "not active" ;
VAL_ 2566882563 PutLeverToNeutral 3 "Not available" 2 "error" 1 "active" 0 "not active" ;
VAL_ 2566882563 PressBrakePedal 3 "Not available" 2 "error" 1 "active" 0 "not active" ;
VAL_ 2566882563 PTO1Active 3 "Not available" 2 "error" 1 "active" 0 "not active" ;
VAL_ 2566882563 PTO2Active 3 "Not available" 2 "error" 1 "active" 0 "not active" ;
VAL_ 2566882563 ManoeuvringMode 3 "Not available" 2 "error" 1 "active" 0 "not active" ;
VAL_ 2566882563 AutomaticMode 3 "Not available" 2 "error" 1 "active" 0 "not active" ;
VAL_ 2566882563 ClutchWear 3 "Not available" 2 "error" 1 "active" 0 "not active" ;
VAL_ 2566801923 TransmissionEngineCrankEnable 3 "Not available" 2 "error" 1 "cranking  allowed" 0 "cranking not allowed" ;
VAL_ 2566801923 TransmissionMode4indicator 3 "Take no action" 2 "Reserved" 1 "Enable" 0 "Disable" ;
VAL_ 2566801923 TransmissionMode3indicator 3 "Take no action" 2 "Reserved" 1 "Enable" 0 "Disable" ;
VAL_ 2566801923 TransmissionMode2indicator 3 "Take no action" 2 "Reserved" 1 "Enable" 0 "Disable" ;
VAL_ 2566801923 TransmissionMode1indicator 3 "Take no action" 2 "Reserved" 1 "Enable" 0 "Disable" ;
VAL_ 2566834735 AmberWarningLampStatus 3 "Not available" 2 "Not available" 1 "on" 0 "off" ;
VAL_ 2566901812 PEPS_RkeCmd 7 "Reserved" 6 "GoHomeAssistance 遥控接近" 5 "Search Car 寻车" 4 "WindowsDown 遥控降窗" 3 "WindowsUp 遥控升窗" 2 "Lock 车门闭锁" 1 "Unlock车门解锁" 0 "Default 默认值" ;
VAL_ 2566901812 PEPS_TrunkSwPress_Resvered 3 "Reserved" 2 "Reserved" 1 "Short Pressed 短按" 0 "Default Value 默认值" ;
VAL_ 2566901812 PEPS_BCMAlarm 15 "Reserved" 14 "Reserved" 13 "Reserved" 12 "Reserved" 11 "Reserved" 10 "Reserved" 9 "Reserved" 8 "Reserved" 7 "Reserved" 6 "Reserved" 5 "Reserved" 4 "Reserved" 3 "Reserved" 2 "Reserved" 1 "10s后未锁车提示" 0 "Start/Default Value 默认值" ;
VAL_ 2566901812 PEPS_ICAlarm 15 "reserved" 5 "Key Battery Low 钥匙电压低报警" 4 "Key Not Found 钥匙没找到报警" 3 "Key Not Found When On/ACC Level Door ClosedON/ACC档时门关没找到钥匙报警" 2 "PEPS failure   PEPS故障" 1 "ESCL failure   ESCL故障" 0 "Start /Default value" ;
VAL_ 2566901812 PEPS_ICInd 15 "reserved" 14 "reserved" 13 "reserved" 12 "reserved" 11 "reserved" 10 "Acc to OFF “进入节能模式”" 9 "emergent start at ACC level indication“请挂空档紧急启动”（MT）" 8 "emergent start at ACC level indication “请挂N档紧急启动”（AT）" 7 "shift gear to neutral position indication “请挂空档熄火”（MT）" 6 "shift gear to N position indication “请挂N档熄火”(AT)" 5 "step on the clutch and press SSB indication “请踩离合启动”(MT)" 4 "step on the brake and press SSB indication “请踩刹车启动”(AT)" 3 "shift gear to neutral position indication When start up “请挂空档启动”（MT）" 2 "shift gear to N position indication When start up “请挂N档启动”（AT）" 1 "backup start indication “备份启动”" 0 "Default" ;
VAL_ 2566901812 PEPS_CurPMM 3 "BPM主控模式(PEPS辅控ECU控制，辅继电器驱动)" 2 "PEPS主控模式3(PEPS主控ECU控制，主继电器和辅继电器同时驱动)" 1 "PEPS主控模式2(PEPS主控ECU控制，辅继电器驱动)" 0 "PEPS主控模式1(PEPS主控ECU控制，主继电器驱动)" ;
VAL_ 2566901812 PEPS_ACC_PROStat 3 "Not available" 2 "error" 1 "enable输出使能" 0 "disable没有输出" ;
VAL_ 2566901812 PEPS_IGN1_PROStat 3 "Not available" 2 "error" 1 "enable输出使能" 0 "disable没有输出" ;
VAL_ 2566901812 PEPS_PkeCmd_Resvered 7 "Reserved" 6 "Reserved" 5 "Reserved" 4 "Reserved" 3 "Trunk Unlock 后背门解锁" 2 "Lock 车门闭锁" 1 "Unlock 车门解锁" 0 "Default 默认值" ;
VAL_ 2566901812 PEPS_IGN2_PROStat 3 "Not available" 2 "error" 1 "enable输出使能" 0 "disable没有输出" ;
VAL_ 2566901812 PEPS_ST_PROStat_Resv 3 "Not available" 2 "error" 1 "enable输出使能" 0 "disable没有输出" ;
VAL_ 2566901812 PEPS_SystemPowerMode 3 "CRANK" 2 "ON" 1 "ACC" 0 "OFF" ;
VAL_ 2566901812 PEPS_MessageType 7 "reserved" 6 "reserved" 5 "Request to restart Authentication" 4 "sendkey" 3 "cancel start" 2 "Emergency start request" 1 "Normal start request" 0 "重新发起认证" 0 "Reserved" ;
VAL_ 2566901812 PEPS_FRSwPress_Resvered 3 "Reserved" 2 "Reserved" 1 "Short Pressed 短按" 0 "Default Value 默认值" ;
VAL_ 2566901812 PEPS_FLSwPress_Resvered 3 "Reserved" 2 "Reserved" 1 "Short Pressed 短按" 0 "Default Value 默认值" ;
VAL_ 2566902068 PEPS_EncryptedStatus 245 "Key Authentication is passed and ESCL is unlocked but the calculation of encrypted response key shall be all 0x00" 240 "ESCL is Locked,the encrypted response key shall be all 0x00" 95 "Key Authentication is Failed, the encrypted response key shall be all 0x00" 0 "Key Authentication is passed and ESCL is unlocked,the encrypted response key shall be checked by EMS" ;
VAL_ 2566910004 PEPS_NM_DA 251 "TBOX" 76 "MP5" 52 "PEPS" 33 "BCM" 25 "EATC" 23 "ICM" ;
VAL_ 2566910004 PEPS_NM_Limphome 1 "Ture" 0 "False" ;
VAL_ 2566910004 PEPS_NM_Sleep_Ind 1 "Ture" 0 "False" ;
VAL_ 2566910004 PEPS_NM_Sleep_Ack 1 "Ture" 0 "False" ;
VAL_ 2566910004 PEPS_NM_Alive 1 "Ture" 0 "False" ;
VAL_ 2566910004 PEPS_NM_Ring 1 "Ture" 0 "False" ;
VAL_ 2566783796 ESCLCommand 3 "error" 2 "ESCL unlock request" 1 "ESCL lock request" 0 "do nothing" ;
VAL_ 2566783796 PowerMode 7 "Not defined" 6 "Not defined" 5 "Not defined" 4 "START(ACC_CTRL = off, IGN_CTRL = on," 3 "ON (Engine ON:ACC_CTRL = on, IGN_CTRL = on, IGN2_CTRL = on, START = off (engine speed >= idle value))" 2 "ON (Engine OFF:ACC_CTRL = on, IGN_CTRL = on, IGN2_CTRL = on, START = off (engine speed < idle value))" 1 "ACC(ACC_CTRL = on, IGN_CTRL = off,IGN2_CTRL = off, START = off)" 0 "IGN2_CTRL=on,START=on)" 0 "IGN2_CTRL=off,START=off)" 0 "OFF(ACC_CTRL = off, ,IGN_CTRL = off," ;
VAL_ 2566783796 PSAliveCounter 0 "Thisisacounterthatincreaseateverymessage.ThissignalensurethatthePSis'live'" ;
VAL_ 2566783796 PS_CRC 0 "ThisistheCRCofallthemessage.ThissignalincreasesthesafetyleveloftheCANmessage" ;
VAL_ 2564640052 Anti_theftEncryptionIndicatorSta 3 "Not_Available" 2 "Not defined" 1 "Encrypted_Code_Present" 0 "Encryption_Seed_Request" ;
VAL_ 2564640052 Anti_theftDesiredExitModeStates 3 "Not_Available" 2 "Not defined" 1 "Lock_When_Key_Off" 0 "Lock_Upon_Operator_Request" ;
VAL_ 2564640052 Anti_theftCommandStates 7 "Not defined" 6 "Not defined" 5 "Login" 4 "Check_Status" 3 "Lock_or_Unlock" 2 "Change_Password" 1 "Delete_Password" 0 "Add_Password" ;
VAL_ 2565865488 RetarderTorqueMode1 8 "扭矩限制是" 7 "ABS开启上电自检" 2 "恒速档" 1 "制动档" ;
VAL_ 2565865488 EngineCoolantLoadIncrease1 3 "Not available" 2 "Error" 1 "油水温超限" 0 "油水温正常" ;
VAL_ 2565865488 RetarderRequestingBrakeLight1 3 "Not available" 2 "Reserved" 1 "Retarder is requesting that the brake lights are illuminated(点亮制动灯)" 0 "Retarder is not requesting that the brake lights are illuminated(不点亮制动灯)" ;
VAL_ 2566852624 RetarderManualShift 5 "5档" 4 "4档" 3 "3档" 2 "2档" 1 "1档" 0 "0档" ;
VAL_ 2566905966 SYSDisplayRequest 2 "error(夜视显示异常)" 1 "请求显示夜视" 0 "关闭显示夜视" ;
VAL_ 2566905966 WORKStatus 3 "resreved" 2 "error" 1 "active" 0 "off" ;
VAL_ 2566905966 PedestrianRecognition 3 "resreved" 2 "error" 1 "active" 0 "off" ;
VAL_ 2566905966 TargetDetection 1 "有目标物" 0 "没有目标物" ;
VAL_ 2566905966 TargetDistanceLevel 3 "距离大于50M" 2 "距离少于50M" 1 "距离少于20M" 0 "距离少于10M" ;
VAL_ 2566905966 TargetDetectionAlarm 2 "严重警告" 1 "一般警告" 0 "正常" ;
VAL_ 2566908272 Radar_Warning_Left 3 "Reserved" 2 "Warning level 2" 1 "Warning level 1" 0 "Inactive" ;
VAL_ 2566908272 Radar_SystemError_Left 1 "Error" 0 "No error" ;
VAL_ 2566908272 Radar_Status_Left 3 "Active （功能开启，满足工作条件）" 2 "Standby（功能开启，未满足车速工作条件）" 1 "Off（关闭状态，被驾驶员开关关闭）" 0 "Reserved" ;
VAL_ 2566908273 Radar_Warning_Right 3 "Reserved" 2 "Warning level 2" 1 "Warning level 1" 0 "Inactive" ;
VAL_ 2566908273 Radar_SystemError_Right 1 "Error" 0 "No error" ;
VAL_ 2566908273 Radar_Status_Right 3 "Active （功能开启，满足工作条件）" 2 "Standby（功能开启，未满足车速工作条件）" 1 "Off（关闭状态，被驾驶员开关关闭）" 0 "Reserved" ;
VAL_ 2564568141 Anti_theftEncryptionSeedPresentI 3 "Not available" 2 "Error" 1 "Random number is present" 0 "Random number is not present" ;
VAL_ 2564568141 Anti_theftPasswordValidIndicator 3 "Not available" 2 "Error" 0 "2Error" 0 "1Passwordisavalidatedpassword" 0 "Password is not a validated password" ;
VAL_ 2564568141 Anti_theftComponentStatusStates 3 "Not defined" 2 "Blocked" 1 "Locked" 0 "Unlocked" ;
VAL_ 2564568141 Anti_theftModifyPasswordStates 3 "Not_valid" 2 "Empty_of_Passwords" 1 "Full_of_Passwords" 0 "Ok" ;
VAL_ 2566784333 ESCLUnlockSensor2Sts 3 "Invalid (initial value)" 2 "Error" 1 "Unlocked sensor 2 active" 0 "Unlocked sensor 2 not active" ;
VAL_ 2566784333 UnlockingRunning 3 "Invalid (initial value)" 2 "Error" 1 "Unlocking is running" 0 "Unlocking is not running" ;
VAL_ 2566784333 ESCLUnlockSensor1Sts 3 "Invalid (initial value)" 2 "Error" 1 "Unlocked sensor 1 active" 0 "Unlocked sensor 1 not active" ;
VAL_ 2566784333 ESCLUnlockSensorsSts 3 "Invalid (initial value)" 2 "Error" 1 "Unlocked sensors active" 0 "Unlocked sensors not active" ;
VAL_ 2566784333 ESCLLockSensorSts 3 "Invalid (initial value)" 2 "Error" 1 "Locked sensor active" 0 "Locked sensor not active" ;
VAL_ 2566784333 LockingRunning 3 "Invalid (initial value)" 2 "Error" 1 "Locking is running" 0 "Locking is not running" ;
VAL_ 2565866755 SelectedGear 251 "park停车" 250 "forward gears" 249 "forward gears" 248 "forward gears" 247 "forward gears" 246 "forward gears" 245 "forward gears" 244 "forward gears" 243 "forward gears" 242 "forward gears" 241 "forward gears" 240 "forward gears" 239 "forward gears" 238 "forward gears" 237 "forward gears" 236 "forward gears" 235 "forward gears" 234 "forward gears" 233 "forward gears" 232 "forward gears" 231 "forward gears" 230 "forward gears" 229 "forward gears" 228 "forward gears" 227 "forward gears" 226 "forward gears" 225 "forward gears" 224 "forward gears" 223 "forward gears" 222 "forward gears" 221 "forward gears" 220 "forward gears" 219 "forward gears" 218 "forward gears" 217 "forward gears" 216 "forward gears" 215 "forward gears" 214 "forward gears" 213 "forward gears" 212 "forward gears" 211 "forward gears" 210 "forward gears" 209 "forward gears" 208 "forward gears" 207 "forward gears" 206 "forward gears" 205 "forward gears" 204 "forward gears" 203 "forward gears" 202 "forward gears" 201 "forward gears" 200 "forward gears" 199 "forward gears" 198 "forward gears" 197 "forward gears" 196 "forward gears" 195 "forward gears" 194 "forward gears" 193 "forward gears" 192 "forward gears" 191 "forward gears" 190 "forward gears" 189 "forward gears" 188 "forward gears" 187 "forward gears" 186 "forward gears" 185 "forward gears" 184 "forward gears" 183 "forward gears" 182 "forward gears" 181 "forward gears" 180 "forward gears" 179 "forward gears" 178 "forward gears" 177 "forward gears" 176 "forward gears" 175 "forward gears" 174 "forward gears" 173 "forward gears" 172 "forward gears" 171 "forward gears" 170 "forward gears" 169 "forward gears" 168 "forward gears" 167 "forward gears" 166 "forward gears" 165 "forward gears" 164 "forward gears" 163 "forward gears" 162 "forward gears" 161 "forward gears" 160 "forward gears" 159 "forward gears" 158 "forward gears" 157 "forward gears" 156 "forward gears" 155 "forward gears" 154 "forward gears" 153 "forward gears" 152 "forward gears" 151 "forward gears" 150 "forward gears" 149 "forward gears" 148 "forward gears" 147 "forward gears" 146 "forward gears" 145 "forward gears" 144 "forward gears" 143 "forward gears" 142 "forward gears" 141 "forward gears" 140 "forward gears" 139 "forward gears" 138 "forward gears" 137 "forward gears" 136 "forward gears" 135 "forward gears" 134 "forward gears" 133 "forward gears" 132 "forward gears" 131 "forward gears" 130 "forward gears" 129 "forward gears" 128 "forward gears" 127 "forward gears" 126 "forward gears" 125 "neutral空档" 124 "reverse gears" 123 "reverse gears" 122 "reverse gears" 121 "reverse gears" 120 "reverse gears" 119 "reverse gears" 118 "reverse gears" 117 "reverse gears" 116 "reverse gears" 115 "reverse gears" 114 "reverse gears" 113 "reverse gears" 112 "reverse gears" 111 "reverse gears" 110 "reverse gears" 109 "reverse gears" 108 "reverse gears" 107 "reverse gears" 106 "reverse gears" 105 "reverse gears" 104 "reverse gears" 103 "reverse gears" 102 "reverse gears" 101 "reverse gears" 100 "reverse gears" 99 "reverse gears" 98 "reverse gears" 97 "reverse gears" 96 "reverse gears" 95 "reverse gears" 94 "reverse gears" 93 "reverse gears" 92 "reverse gears" 91 "reverse gears" 90 "reverse gears" 89 "reverse gears" 88 "reverse gears" 87 "reverse gears" 86 "reverse gears" 85 "reverse gears" 84 "reverse gears" 83 "reverse gears" 82 "reverse gears" 81 "reverse gears" 80 "reverse gears" 79 "reverse gears" 78 "reverse gears" 77 "reverse gears" 76 "reverse gears" 75 "reverse gears" 74 "reverse gears" 73 "reverse gears" 72 "reverse gears" 71 "reverse gears" 70 "reverse gears" 69 "reverse gears" 68 "reverse gears" 67 "reverse gears" 66 "reverse gears" 65 "reverse gears" 64 "reverse gears" 63 "reverse gears" 62 "reverse gears" 61 "reverse gears" 60 "reverse gears" 59 "reverse gears" 58 "reverse gears" 57 "reverse gears" 56 "reverse gears" 55 "reverse gears" 54 "reverse gears" 53 "reverse gears" 52 "reverse gears" 51 "reverse gears" 50 "reverse gears" 49 "reverse gears" 48 "reverse gears" 47 "reverse gears" 46 "reverse gears" 45 "reverse gears" 44 "reverse gears" 43 "reverse gears" 42 "reverse gears" 41 "reverse gears" 40 "reverse gears" 39 "reverse gears" 38 "reverse gears" 37 "reverse gears" 36 "reverse gears" 35 "reverse gears" 34 "reverse gears" 33 "reverse gears" 32 "reverse gears" 31 "reverse gears" 30 "reverse gears" 29 "reverse gears" 28 "reverse gears" 27 "reverse gears" 26 "reverse gears" 25 "reverse gears" 24 "reverse gears" 23 "reverse gears" 22 "reverse gears" 21 "reverse gears" 20 "reverse gears" 19 "reverse gears" 18 "reverse gears" 17 "reverse gears" 16 "reverse gears" 15 "reverse gears" 14 "reverse gears" 13 "reverse gears" 12 "reverse gears" 11 "reverse gears" 10 "reverse gears" 9 "reverse gears" 8 "reverse gears" 7 "reverse gears" 6 "reverse gears" 5 "reverse gears" 4 "reverse gears" 3 "reverse gears" 2 "reverse gears" 1 "reverse gears" 0 "reverse gears" ;
VAL_ 2565866755 CurrentGear 251 "park停车" 250 "forward gears" 249 "forward gears" 248 "forward gears" 247 "forward gears" 246 "forward gears" 245 "forward gears" 244 "forward gears" 243 "forward gears" 242 "forward gears" 241 "forward gears" 240 "forward gears" 239 "forward gears" 238 "forward gears" 237 "forward gears" 236 "forward gears" 235 "forward gears" 234 "forward gears" 233 "forward gears" 232 "forward gears" 231 "forward gears" 230 "forward gears" 229 "forward gears" 228 "forward gears" 227 "forward gears" 226 "forward gears" 225 "forward gears" 224 "forward gears" 223 "forward gears" 222 "forward gears" 221 "forward gears" 220 "forward gears" 219 "forward gears" 218 "forward gears" 217 "forward gears" 216 "forward gears" 215 "forward gears" 214 "forward gears" 213 "forward gears" 212 "forward gears" 211 "forward gears" 210 "forward gears" 209 "forward gears" 208 "forward gears" 207 "forward gears" 206 "forward gears" 205 "forward gears" 204 "forward gears" 203 "forward gears" 202 "forward gears" 201 "forward gears" 200 "forward gears" 199 "forward gears" 198 "forward gears" 197 "forward gears" 196 "forward gears" 195 "forward gears" 194 "forward gears" 193 "forward gears" 192 "forward gears" 191 "forward gears" 190 "forward gears" 189 "forward gears" 188 "forward gears" 187 "forward gears" 186 "forward gears" 185 "forward gears" 184 "forward gears" 183 "forward gears" 182 "forward gears" 181 "forward gears" 180 "forward gears" 179 "forward gears" 178 "forward gears" 177 "forward gears" 176 "forward gears" 175 "forward gears" 174 "forward gears" 173 "forward gears" 172 "forward gears" 171 "forward gears" 170 "forward gears" 169 "forward gears" 168 "forward gears" 167 "forward gears" 166 "forward gears" 165 "forward gears" 164 "forward gears" 163 "forward gears" 162 "forward gears" 161 "forward gears" 160 "forward gears" 159 "forward gears" 158 "forward gears" 157 "forward gears" 156 "forward gears" 155 "forward gears" 154 "forward gears" 153 "forward gears" 152 "forward gears" 151 "forward gears" 150 "forward gears" 149 "forward gears" 148 "forward gears" 147 "forward gears" 146 "forward gears" 145 "forward gears" 144 "forward gears" 143 "forward gears" 142 "forward gears" 141 "forward gears" 140 "forward gears" 139 "forward gears" 138 "forward gears" 137 "forward gears" 136 "forward gears" 135 "forward gears" 134 "forward gears" 133 "forward gears" 132 "forward gears" 131 "forward gears" 130 "forward gears" 129 "forward gears" 128 "forward gears" 127 "forward gears" 126 "forward gears" 125 "neutral空档" 124 "reverse gears" 123 "reverse gears" 122 "reverse gears" 121 "reverse gears" 120 "reverse gears" 119 "reverse gears" 118 "reverse gears" 117 "reverse gears" 116 "reverse gears" 115 "reverse gears" 114 "reverse gears" 113 "reverse gears" 112 "reverse gears" 111 "reverse gears" 110 "reverse gears" 109 "reverse gears" 108 "reverse gears" 107 "reverse gears" 106 "reverse gears" 105 "reverse gears" 104 "reverse gears" 103 "reverse gears" 102 "reverse gears" 101 "reverse gears" 100 "reverse gears" 99 "reverse gears" 98 "reverse gears" 97 "reverse gears" 96 "reverse gears" 95 "reverse gears" 94 "reverse gears" 93 "reverse gears" 92 "reverse gears" 91 "reverse gears" 90 "reverse gears" 89 "reverse gears" 88 "reverse gears" 87 "reverse gears" 86 "reverse gears" 85 "reverse gears" 84 "reverse gears" 83 "reverse gears" 82 "reverse gears" 81 "reverse gears" 80 "reverse gears" 79 "reverse gears" 78 "reverse gears" 77 "reverse gears" 76 "reverse gears" 75 "reverse gears" 74 "reverse gears" 73 "reverse gears" 72 "reverse gears" 71 "reverse gears" 70 "reverse gears" 69 "reverse gears" 68 "reverse gears" 67 "reverse gears" 66 "reverse gears" 65 "reverse gears" 64 "reverse gears" 63 "reverse gears" 62 "reverse gears" 61 "reverse gears" 60 "reverse gears" 59 "reverse gears" 58 "reverse gears" 57 "reverse gears" 56 "reverse gears" 55 "reverse gears" 54 "reverse gears" 53 "reverse gears" 52 "reverse gears" 51 "reverse gears" 50 "reverse gears" 49 "reverse gears" 48 "reverse gears" 47 "reverse gears" 46 "reverse gears" 45 "reverse gears" 44 "reverse gears" 43 "reverse gears" 42 "reverse gears" 41 "reverse gears" 40 "reverse gears" 39 "reverse gears" 38 "reverse gears" 37 "reverse gears" 36 "reverse gears" 35 "reverse gears" 34 "reverse gears" 33 "reverse gears" 32 "reverse gears" 31 "reverse gears" 30 "reverse gears" 29 "reverse gears" 28 "reverse gears" 27 "reverse gears" 26 "reverse gears" 25 "reverse gears" 24 "reverse gears" 23 "reverse gears" 22 "reverse gears" 21 "reverse gears" 20 "reverse gears" 19 "reverse gears" 18 "reverse gears" 17 "reverse gears" 16 "reverse gears" 15 "reverse gears" 14 "reverse gears" 13 "reverse gears" 12 "reverse gears" 11 "reverse gears" 10 "reverse gears" 9 "reverse gears" 8 "reverse gears" 7 "reverse gears" 6 "reverse gears" 5 "reverse gears" 4 "reverse gears" 3 "reverse gears" 2 "reverse gears" 1 "reverse gears" 0 "reverse gears" ;
VAL_ 2566845555 CTIWheelEndElectricalFault 3 "Reserved" 2 "Reserved" 1 "in 20 min without signal(表示20分钟内未收到该轮胎信号)" 0 "normal （正常）" ;
VAL_ 2566845555 CTITireStatus 3 "Reserved" 2 "Reserved" 1 "Rapid Air Leakage（轮胎漏气）" 0 "normal （正常）" ;
